VERSION ""

NS_ :

BS_:

BU_: DEBUG BMS DCM FSM PDM DIM INVL INVR

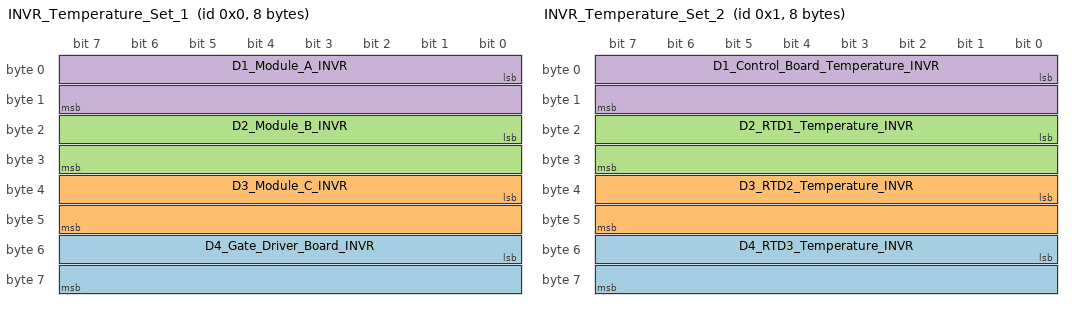
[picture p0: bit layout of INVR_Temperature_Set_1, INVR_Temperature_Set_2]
BO_ 0 INVR_Temperature_Set_1: 8 INVR
SG_ D4_Gate_Driver_Board_INVR : 48|16@1- (0.1,0) [-3276.8|3276.7] "degC" DEBUG
SG_ D3_Module_C_INVR : 32|16@1- (0.1,0) [-3276.8|3276.7] "degC" DEBUG
SG_ D2_Module_B_INVR : 16|16@1- (0.1,0) [-3276.8|3276.7] "degC" DEBUG
SG_ D1_Module_A_INVR : 0|16@1- (0.1,0) [-3276.8|3276.7] "degC" DEBUG

BO_ 1 INVR_Temperature_Set_2: 8 INVR
SG_ D4_RTD3_Temperature_INVR : 48|16@1- (0.1,0) [-3276.8|3276.7] "degC" DEBUG
SG_ D3_RTD2_Temperature_INVR : 32|16@1- (0.1,0) [-3276.8|3276.7] "degC" DEBUG
SG_ D2_RTD1_Temperature_INVR : 16|16@1- (0.1,0) [-3276.8|3276.7] "degC" DEBUG
SG_ D1_Control_Board_Temperature_INVR : 0|16@1- (0.1,0) [-3276.8|3276.7] "degC" DEBUG

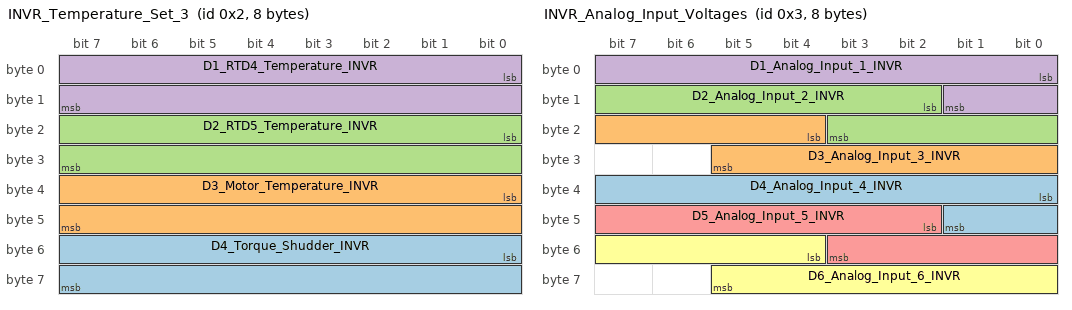
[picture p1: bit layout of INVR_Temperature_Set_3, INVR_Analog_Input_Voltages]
BO_ 2 INVR_Temperature_Set_3: 8 INVR
SG_ D4_Torque_Shudder_INVR : 48|16@1- (0.1,0) [-3276.8|3276.7] "Nm" DEBUG
SG_ D3_Motor_Temperature_INVR : 32|16@1- (0.1,0) [-3276.8|3276.7] "degC" DEBUG
SG_ D2_RTD5_Temperature_INVR : 16|16@1- (0.1,0) [-3276.8|3276.7] "degC" DEBUG
SG_ D1_RTD4_Temperature_INVR : 0|16@1- (0.1,0) [-3276.8|3276.7] "degC" DEBUG

BO_ 3 INVR_Analog_Input_Voltages: 8 INVR
SG_ D4_Analog_Input_4_INVR : 32|10@1+ (0.01,0) [0|10.23] "V" DEBUG
SG_ D3_Analog_Input_3_INVR : 20|10@1+ (0.01,0) [0|10.23] "V" DEBUG
SG_ D2_Analog_Input_2_INVR : 10|10@1+ (0.01,0) [0|10.23] "V" DEBUG
SG_ D1_Analog_Input_1_INVR : 0|10@1+ (0.01,0) [0|10.23] "V" DEBUG
SG_ D5_Analog_Input_5_INVR : 42|10@1+ (0.01,0) [0|10.23] "V" DEBUG
SG_ D6_Analog_Input_6_INVR : 52|10@1+ (0.01,0) [0|10.23] "V" DEBUG

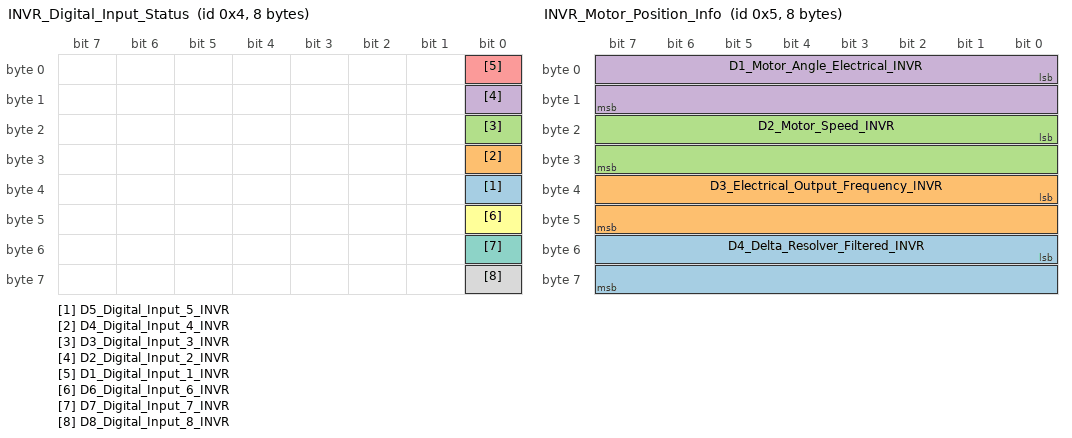
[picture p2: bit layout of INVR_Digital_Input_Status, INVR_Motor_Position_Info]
BO_ 4 INVR_Digital_Input_Status: 8 INVR
SG_ D5_Digital_Input_5_INVR : 32|1@1+ (1,0) [0|1] "boolean" DEBUG
SG_ D4_Digital_Input_4_INVR : 24|1@1+ (1,0) [0|1] "boolean" DEBUG
SG_ D3_Digital_Input_3_INVR : 16|1@1+ (1,0) [0|1] "boolean" DEBUG
SG_ D2_Digital_Input_2_INVR : 8|1@1+ (1,0) [0|1] "boolean" DEBUG
SG_ D1_Digital_Input_1_INVR : 0|1@1+ (1,0) [0|1] "boolean" DEBUG
SG_ D6_Digital_Input_6_INVR : 40|1@1+ (1,0) [0|1] "boolean" DEBUG
SG_ D7_Digital_Input_7_INVR : 48|1@1+ (1,0) [0|1] "boolean" DEBUG
SG_ D8_Digital_Input_8_INVR : 56|1@1+ (1,0) [0|1] "boolean" DEBUG

BO_ 5 INVR_Motor_Position_Info: 8 INVR
SG_ D4_Delta_Resolver_Filtered_INVR : 48|16@1- (0.1,0) [-3276.8|3276.7] "deg" DEBUG
SG_ D3_Electrical_Output_Frequency_INVR : 32|16@1- (0.1,0) [-3276.8|3276.7] "hz" DEBUG
SG_ D2_Motor_Speed_INVR : 16|16@1- (1,0) [-32768|32767] "rpm" DEBUG
SG_ D1_Motor_Angle_Electrical_INVR : 0|16@1+ (0.1,0) [0|6553.5] "deg" DEBUG

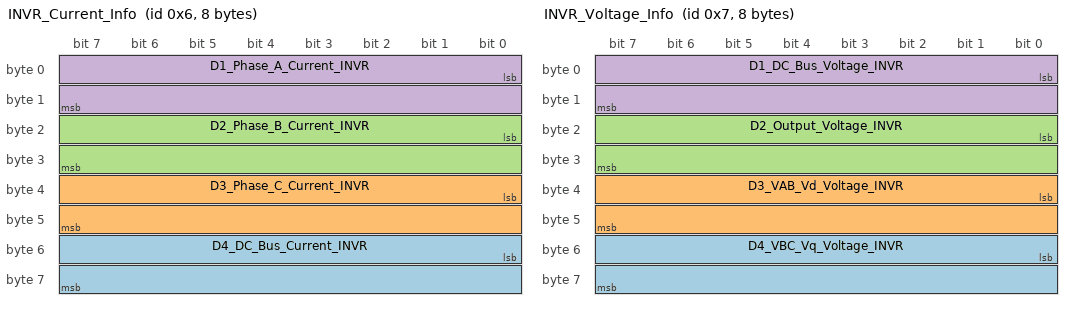
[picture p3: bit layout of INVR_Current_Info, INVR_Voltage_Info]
BO_ 6 INVR_Current_Info: 8 INVR
SG_ D4_DC_Bus_Current_INVR : 48|16@1- (0.1,0) [-3276.8|3276.7] "A" DEBUG
SG_ D3_Phase_C_Current_INVR : 32|16@1- (0.1,0) [-3276.8|3276.7] "A" DEBUG
SG_ D2_Phase_B_Current_INVR : 16|16@1- (0.1,0) [-3276.8|3276.7] "A" DEBUG
SG_ D1_Phase_A_Current_INVR : 0|16@1- (0.1,0) [-3276.8|3276.7] "A" DEBUG

BO_ 7 INVR_Voltage_Info: 8 INVR
SG_ D4_VBC_Vq_Voltage_INVR : 48|16@1- (0.1,0) [-3276.8|3276.7] "V" DEBUG
SG_ D3_VAB_Vd_Voltage_INVR : 32|16@1- (0.1,0) [-3276.8|3276.7] "V" DEBUG
SG_ D2_Output_Voltage_INVR : 16|16@1- (0.1,0) [-3276.8|3276.7] "V" DEBUG
SG_ D1_DC_Bus_Voltage_INVR : 0|16@1- (0.1,0) [-3276.8|3276.7] "V" DEBUG

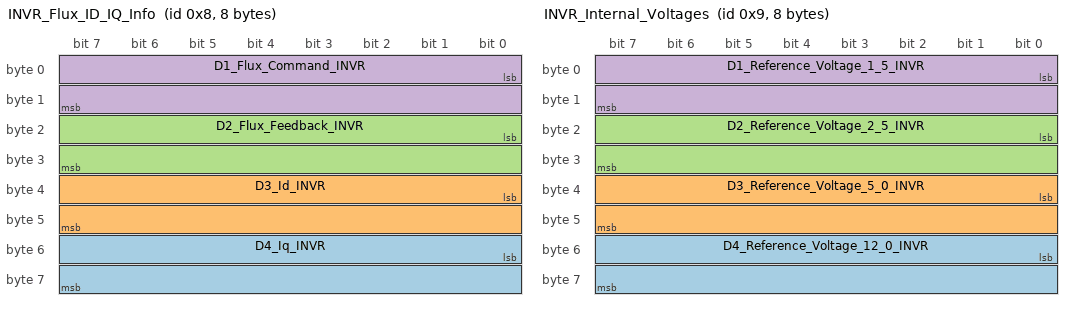
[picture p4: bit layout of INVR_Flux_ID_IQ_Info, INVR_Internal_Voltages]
BO_ 8 INVR_Flux_ID_IQ_Info: 8 INVR
SG_ D4_Iq_INVR : 48|16@1- (0.1,0) [-3276.8|3276.7] "A" DEBUG
SG_ D3_Id_INVR : 32|16@1- (0.1,0) [-3276.8|3276.7] "A" DEBUG
SG_ D2_Flux_Feedback_INVR : 16|16@1- (0.001,0) [-32.768|32.767] "Wb" DEBUG
SG_ D1_Flux_Command_INVR : 0|16@1- (0.001,0) [-32.768|32.767] "Wb" DEBUG

BO_ 9 INVR_Internal_Voltages: 8 INVR
SG_ D4_Reference_Voltage_12_0_INVR : 48|16@1- (0.01,0) [-327.68|327.67] "V" DEBUG
SG_ D3_Reference_Voltage_5_0_INVR : 32|16@1- (0.01,0) [-327.68|327.67] "V" DEBUG
SG_ D2_Reference_Voltage_2_5_INVR : 16|16@1- (0.01,0) [-327.68|327.67] "V" DEBUG
SG_ D1_Reference_Voltage_1_5_INVR : 0|16@1- (0.01,0) [-327.68|327.67] "V" DEBUG

BO_ 10 INVR_Internal_States: 8 INVR
SG_ D7_Direction_Command_INVR : 56|1@1+ (1,0) [0|1] "" DEBUG
SG_ D6_Inverter_Enable_State_INVR : 48|1@1+ (1,0) [0|1] "" DEBUG
SG_ D3_Relay_3_Status_INVR : 26|1@1+ (1,0) [0|1] "" DEBUG
SG_ D3_Relay_4_Status_INVR : 27|1@1+ (1,0) [0|1] "" DEBUG
SG_ D3_Relay_2_Status_INVR : 25|1@1+ (1,0) [0|1] "" DEBUG
SG_ D4_Inverter_Run_Mode_INVR : 32|1@1+ (1,0) [0|1] "" DEBUG
SG_ D5_Inverter_Command_Mode_INVR : 40|1@1+ (1,0) [0|1] "" DEBUG
SG_ D3_Relay_1_Status_INVR : 24|1@1+ (1,0) [0|1] "" DEBUG
SG_ D2_Inverter_State_INVR : 16|8@1+ (1,0) [0|255] "" DEBUG
SG_ D1_VSM_State_INVR : 0|8@1+ (1,0) [0|15] "" DCM
SG_ D6_Inverter_Enable_Lockout_INVR : 55|1@1+ (1,0) [0|1] "" DEBUG
SG_ D4_Inverter_Discharge_State_INVR : 37|3@1+ (1,0) [0|7] "" DEBUG
SG_ D3_Relay_5_Status_INVR : 28|1@1+ (1,0) [0|1] "" DEBUG
SG_ D3_Relay_6_Status_INVR : 29|1@1+ (1,0) [0|1] "" DEBUG
SG_ D7_BMS_Active_INVR : 57|1@1+ (1,0) [0|1] "" DEBUG
SG_ D7_BMS_Torque_Limiting_INVR : 58|1@1+ (1,0) [0|1] "" DEBUG
SG_ D7_Max_Speed_Limiting_INVR : 59|1@1+ (1,0) [0|1] "" DEBUG
SG_ D7_Low_Speed_Limiting_INVR : 61|1@1+ (1,0) [0|1] "" DEBUG
SG_ D5_Rolling_Counter_INVR : 44|4@1+ (1,0) [0|15] "" DEBUG
SG_ D1_PWM_Frequency_INVR : 8|8@1+ (1,0) [0|255] "kHz" DEBUG
SG_ D6_Start_Mode_Active_INVR : 54|1@1+ (1,0) [0|1] "" DEBUG

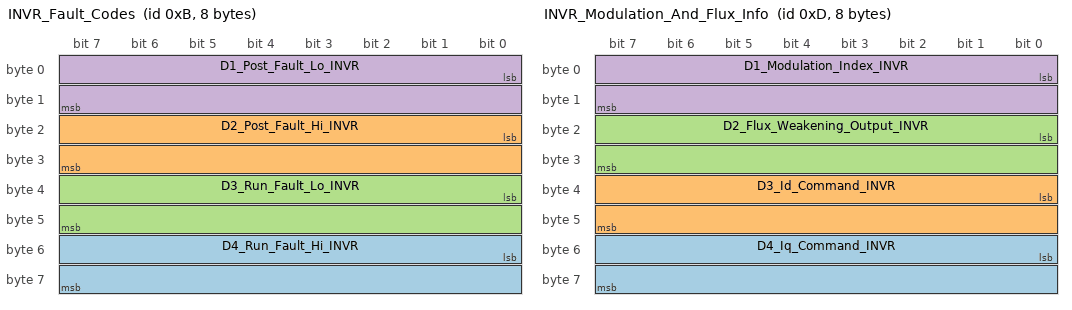
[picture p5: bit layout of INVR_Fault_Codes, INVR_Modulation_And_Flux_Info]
BO_ 11 INVR_Fault_Codes: 8 INVR
SG_ D4_Run_Fault_Hi_INVR : 48|16@1+ (1,0) [0|65535] "" DEBUG
SG_ D2_Post_Fault_Hi_INVR : 16|16@1+ (1,0) [0|65535] "" DEBUG
SG_ D3_Run_Fault_Lo_INVR : 32|16@1+ (1,0) [0|65535] "" DEBUG
SG_ D1_Post_Fault_Lo_INVR : 0|16@1+ (1,0) [0|65535] "" DEBUG

BO_ 12 INVR_Torque_And_Timer_Info: 8 INVR
SG_ D3_Power_On_Timer_INVR : 32|32@1+ (0.003,0) [0|12884800] "Sec" DEBUG
SG_ D2_Torque_Feedback_INVR : 16|16@1- (0.1,0) [-3276.8|3276.7] "Nm" DEBUG
SG_ D1_Commanded_Torque_INVR : 0|16@1- (0.1,0) [-3276.8|3276.7] "Nm" DEBUG

BO_ 13 INVR_Modulation_And_Flux_Info: 8 INVR
SG_ D4_Iq_Command_INVR : 48|16@1- (0.1,0) [-3276.8|3276.7] "A" DEBUG
SG_ D3_Id_Command_INVR : 32|16@1- (0.1,0) [-3276.8|3276.7] "A" DEBUG
SG_ D2_Flux_Weakening_Output_INVR : 16|16@1- (0.1,0) [-3276.8|3276.7] "A" DEBUG
SG_ D1_Modulation_Index_INVR : 0|16@1- (0.0001,0) [-3.2768|3.2767] "" DEBUG

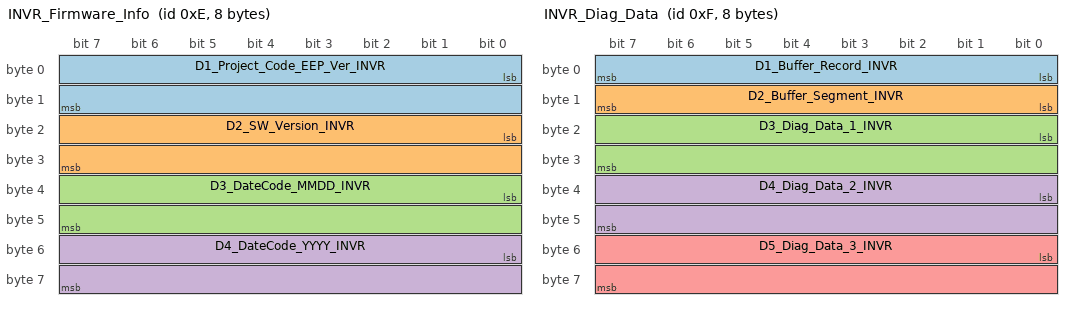
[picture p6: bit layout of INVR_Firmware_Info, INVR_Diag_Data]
BO_ 14 INVR_Firmware_Info: 8 INVR
SG_ D1_Project_Code_EEP_Ver_INVR : 0|16@1+ (1,0) [0|65535] "" DEBUG
SG_ D2_SW_Version_INVR : 16|16@1+ (1,0) [0|65535] "" DEBUG
SG_ D3_DateCode_MMDD_INVR : 32|16@1+ (1,0) [0|65535] "" DEBUG
SG_ D4_DateCode_YYYY_INVR : 48|16@1+ (1,0) [0|65535] "" DEBUG

BO_ 15 INVR_Diag_Data : 8 INVR
SG_ D1_Buffer_Record_INVR : 0|8@1+ (1,0) [0|255] "" DEBUG
SG_ D2_Buffer_Segment_INVR : 8|8@1+ (1,0) [0|5] "" DEBUG
SG_ D3_Diag_Data_1_INVR : 16|16@1- (1,0) [-32768|32767] "" DEBUG
SG_ D4_Diag_Data_2_INVR : 32|16@1- (1,0) [-32768|32767] "" DEBUG
SG_ D5_Diag_Data_3_INVR : 48|16@1- (1,0) [-32768|32767] "" DEBUG

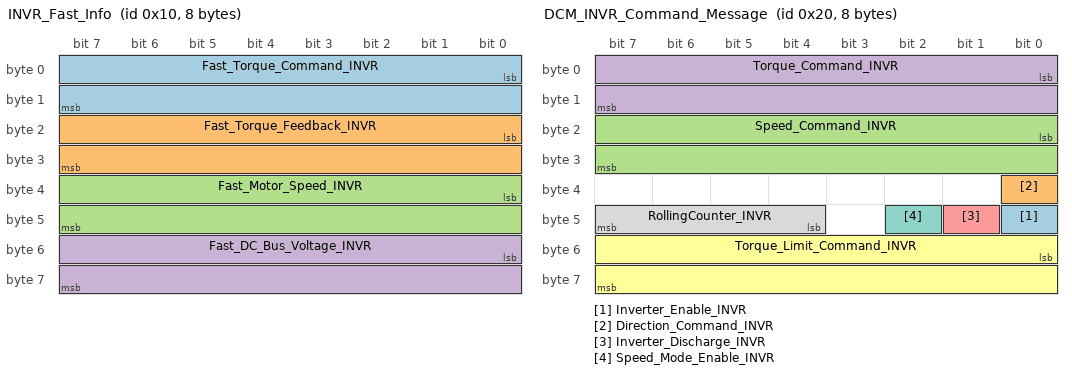
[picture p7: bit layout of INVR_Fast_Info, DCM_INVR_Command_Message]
BO_ 16 INVR_Fast_Info: 8 INVR
SG_ Fast_Torque_Command_INVR : 0|16@1- (0.1,0) [-3276.8|3276.7] "Nm" DEBUG
SG_ Fast_Torque_Feedback_INVR : 16|16@1- (0.1,0) [-3276.8|3276.7] "Nm" DEBUG
SG_ Fast_Motor_Speed_INVR : 32|16@1- (1,0) [-32768|32767] "rpm" DEBUG
SG_ Fast_DC_Bus_Voltage_INVR : 48|16@1- (0.1,0) [-3276.8|3276.7] "V" DEBUG

BO_ 32 DCM_INVR_Command_Message: 8 DCM
SG_ Inverter_Enable_INVR : 40|1@1+ (1,0) [0|1] "Bit" INVR
SG_ Direction_Command_INVR : 32|1@1+ (1,0) [0|1] "Bit" INVR
SG_ Speed_Command_INVR : 16|16@1- (1,0) [-32768|32767] "rpm" INVR
SG_ Torque_Command_INVR : 0|16@1- (0.1,0) [-3276.8|3276.7] "Nm" INVR
SG_ Inverter_Discharge_INVR : 41|1@1+ (1,0) [0|1] "Bit" INVR
SG_ Torque_Limit_Command_INVR : 48|16@1- (0.1,0) [-3276.8|3276.7] "Nm" INVR
SG_ Speed_Mode_Enable_INVR : 42|1@1+ (1,0) [0|1] "Bit" INVR
SG_ RollingCounter_INVR : 44|4@1+ (1,0) [0|15] "Bits" INVR

BO_ 33 DEBUG_INVR_Read_Write_Param_Command: 8 DEBUG
SG_ D3_Data_Command : 32|16@1- (1,0) [-32768|32767] "" INVR
SG_ D2_Read_Write_Command : 16|1@1+ (1,0) [0|1] "" INVR
SG_ D1_Parameter_Address_Command : 0|16@1+ (1,0) [0|65535] "" INVR

BO_ 34 INVR_DEBUG_Read_Write_Param_Response: 8 INVR
SG_ D2_Write_Success : 16|1@1+ (1,0) [0|1] "" DEBUG
SG_ D3_Data_Response : 32|16@1- (1,0) [-32768|32767] "" DEBUG
SG_ D1_Parameter_Address_Response : 0|16@1+ (1,0) [0|65535] "" DEBUG

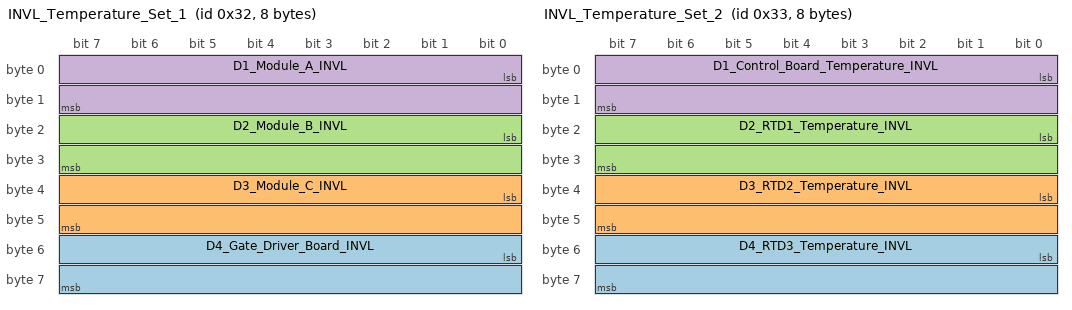
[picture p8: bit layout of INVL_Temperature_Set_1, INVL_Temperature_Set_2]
BO_ 50 INVL_Temperature_Set_1: 8 INVL
SG_ D4_Gate_Driver_Board_INVL : 48|16@1- (0.1,0) [-3276.8|3276.7] "degC" DEBUG
SG_ D3_Module_C_INVL : 32|16@1- (0.1,0) [-3276.8|3276.7] "degC" DEBUG
SG_ D2_Module_B_INVL : 16|16@1- (0.1,0) [-3276.8|3276.7] "degC" DEBUG
SG_ D1_Module_A_INVL : 0|16@1- (0.1,0) [-3276.8|3276.7] "degC" DEBUG

BO_ 51 INVL_Temperature_Set_2: 8 INVL
SG_ D4_RTD3_Temperature_INVL : 48|16@1- (0.1,0) [-3276.8|3276.7] "degC" DEBUG
SG_ D3_RTD2_Temperature_INVL : 32|16@1- (0.1,0) [-3276.8|3276.7] "degC" DEBUG
SG_ D2_RTD1_Temperature_INVL : 16|16@1- (0.1,0) [-3276.8|3276.7] "degC" DEBUG
SG_ D1_Control_Board_Temperature_INVL : 0|16@1- (0.1,0) [-3276.8|3276.7] "degC" DEBUG

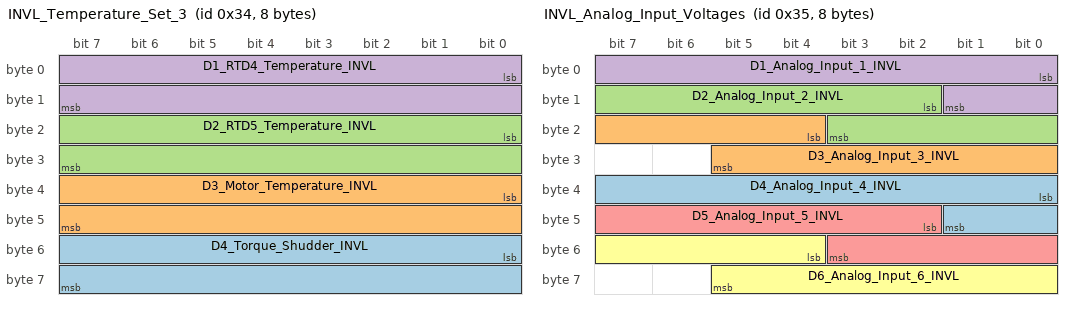
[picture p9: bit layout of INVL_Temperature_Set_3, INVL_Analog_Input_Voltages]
BO_ 52 INVL_Temperature_Set_3: 8 INVL
SG_ D4_Torque_Shudder_INVL : 48|16@1- (0.1,0) [-3276.8|3276.7] "Nm" DEBUG
SG_ D3_Motor_Temperature_INVL : 32|16@1- (0.1,0) [-3276.8|3276.7] "degC" DEBUG
SG_ D2_RTD5_Temperature_INVL : 16|16@1- (0.1,0) [-3276.8|3276.7] "degC" DEBUG
SG_ D1_RTD4_Temperature_INVL : 0|16@1- (0.1,0) [-3276.8|3276.7] "degC" DEBUG

BO_ 53 INVL_Analog_Input_Voltages: 8 INVL
SG_ D4_Analog_Input_4_INVL : 32|10@1+ (0.01,0) [0|10.23] "V" DEBUG
SG_ D3_Analog_Input_3_INVL : 20|10@1+ (0.01,0) [0|10.23] "V" DEBUG
SG_ D2_Analog_Input_2_INVL : 10|10@1+ (0.01,0) [0|10.23] "V" DEBUG
SG_ D1_Analog_Input_1_INVL : 0|10@1+ (0.01,0) [0|10.23] "V" DEBUG
SG_ D5_Analog_Input_5_INVL : 42|10@1+ (0.01,0) [0|10.23] "V" DEBUG
SG_ D6_Analog_Input_6_INVL : 52|10@1+ (0.01,0) [0|10.23] "V" DEBUG

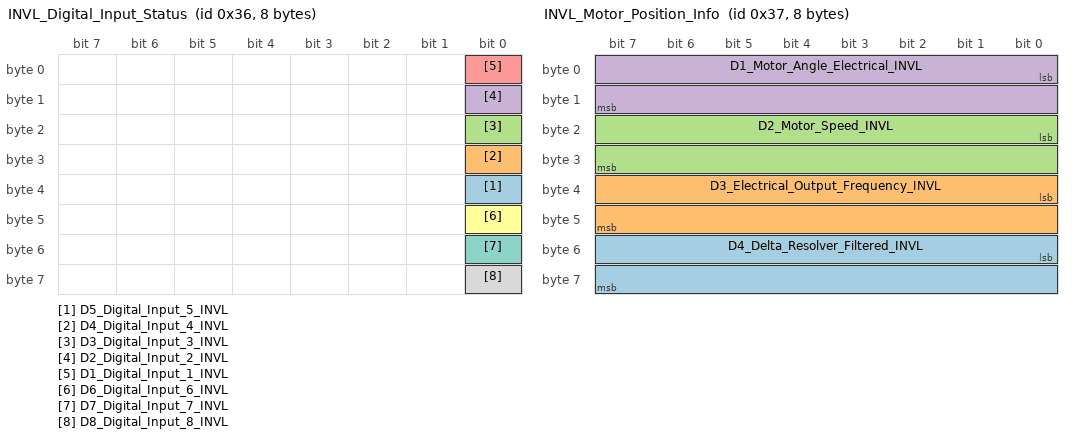
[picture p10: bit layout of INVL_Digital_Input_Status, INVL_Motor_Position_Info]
BO_ 54 INVL_Digital_Input_Status: 8 INVL
SG_ D5_Digital_Input_5_INVL : 32|1@1+ (1,0) [0|1] "boolean" DEBUG
SG_ D4_Digital_Input_4_INVL : 24|1@1+ (1,0) [0|1] "boolean" DEBUG
SG_ D3_Digital_Input_3_INVL : 16|1@1+ (1,0) [0|1] "boolean" DEBUG
SG_ D2_Digital_Input_2_INVL : 8|1@1+ (1,0) [0|1] "boolean" DEBUG
SG_ D1_Digital_Input_1_INVL : 0|1@1+ (1,0) [0|1] "boolean" DEBUG
SG_ D6_Digital_Input_6_INVL : 40|1@1+ (1,0) [0|1] "boolean" DEBUG
SG_ D7_Digital_Input_7_INVL : 48|1@1+ (1,0) [0|1] "boolean" DEBUG
SG_ D8_Digital_Input_8_INVL : 56|1@1+ (1,0) [0|1] "boolean" DEBUG

BO_ 55 INVL_Motor_Position_Info: 8 INVL
SG_ D4_Delta_Resolver_Filtered_INVL : 48|16@1- (0.1,0) [-3276.8|3276.7] "deg" DEBUG
SG_ D3_Electrical_Output_Frequency_INVL : 32|16@1- (0.1,0) [-3276.8|3276.7] "hz" DEBUG
SG_ D2_Motor_Speed_INVL : 16|16@1- (1,0) [-32768|32767] "rpm" DEBUG
SG_ D1_Motor_Angle_Electrical_INVL : 0|16@1+ (0.1,0) [0|6553.5] "deg" DEBUG

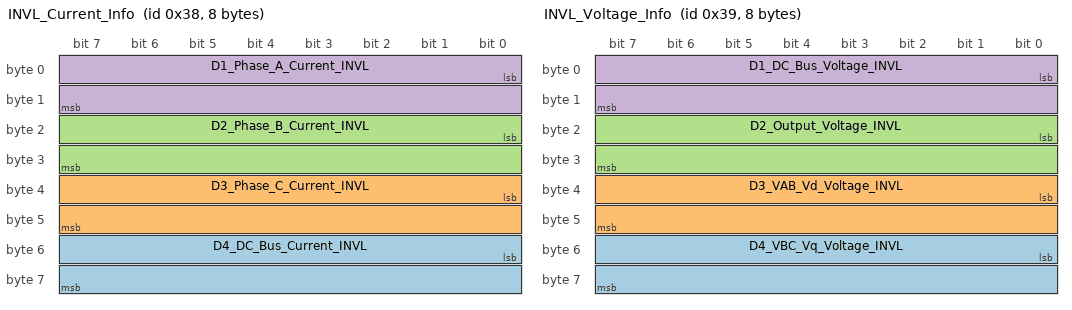
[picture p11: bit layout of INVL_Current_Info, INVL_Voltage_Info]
BO_ 56 INVL_Current_Info: 8 INVL
SG_ D4_DC_Bus_Current_INVL : 48|16@1- (0.1,0) [-3276.8|3276.7] "A" DEBUG
SG_ D3_Phase_C_Current_INVL : 32|16@1- (0.1,0) [-3276.8|3276.7] "A" DEBUG
SG_ D2_Phase_B_Current_INVL : 16|16@1- (0.1,0) [-3276.8|3276.7] "A" DEBUG
SG_ D1_Phase_A_Current_INVL : 0|16@1- (0.1,0) [-3276.8|3276.7] "A" DEBUG

BO_ 57 INVL_Voltage_Info: 8 INVL
SG_ D4_VBC_Vq_Voltage_INVL : 48|16@1- (0.1,0) [-3276.8|3276.7] "V" DEBUG
SG_ D3_VAB_Vd_Voltage_INVL : 32|16@1- (0.1,0) [-3276.8|3276.7] "V" DEBUG
SG_ D2_Output_Voltage_INVL : 16|16@1- (0.1,0) [-3276.8|3276.7] "V" DEBUG
SG_ D1_DC_Bus_Voltage_INVL : 0|16@1- (0.1,0) [-3276.8|3276.7] "V" DEBUG

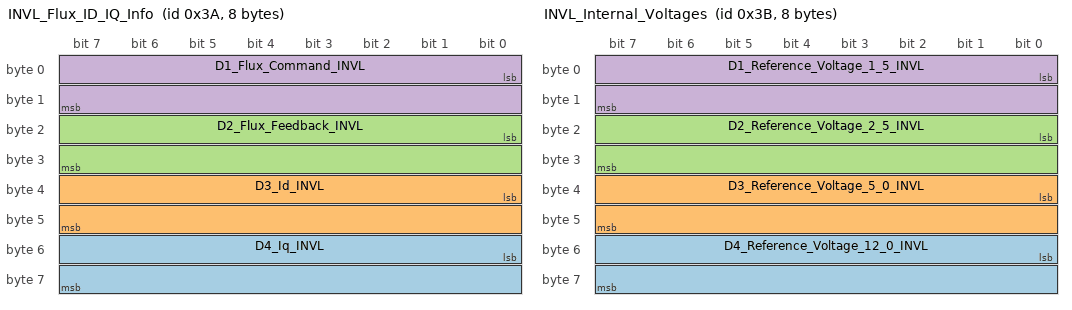
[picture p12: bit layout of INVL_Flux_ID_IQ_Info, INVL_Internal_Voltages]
BO_ 58 INVL_Flux_ID_IQ_Info: 8 INVL
SG_ D4_Iq_INVL : 48|16@1- (0.1,0) [-3276.8|3276.7] "A" DEBUG
SG_ D3_Id_INVL : 32|16@1- (0.1,0) [-3276.8|3276.7] "A" DEBUG
SG_ D2_Flux_Feedback_INVL : 16|16@1- (0.001,0) [-32.768|32.767] "Wb" DEBUG
SG_ D1_Flux_Command_INVL : 0|16@1- (0.001,0) [-32.768|32.767] "Wb" DEBUG

BO_ 59 INVL_Internal_Voltages: 8 INVL
SG_ D4_Reference_Voltage_12_0_INVL : 48|16@1- (0.01,0) [-327.68|327.67] "V" DEBUG
SG_ D3_Reference_Voltage_5_0_INVL : 32|16@1- (0.01,0) [-327.68|327.67] "V" DEBUG
SG_ D2_Reference_Voltage_2_5_INVL : 16|16@1- (0.01,0) [-327.68|327.67] "V" DEBUG
SG_ D1_Reference_Voltage_1_5_INVL : 0|16@1- (0.01,0) [-327.68|327.67] "V" DEBUG

BO_ 60 INVL_Internal_States: 8 INVL
SG_ D7_Direction_Command_INVL : 56|1@1+ (1,0) [0|1] "" DEBUG
SG_ D6_Inverter_Enable_State_INVL : 48|1@1+ (1,0) [0|1] "" DEBUG
SG_ D3_Relay_3_Status_INVL : 26|1@1+ (1,0) [0|1] ""  DEBUG
SG_ D3_Relay_4_Status_INVL : 27|1@1+ (1,0) [0|1] ""  DEBUG
SG_ D3_Relay_2_Status_INVL : 25|1@1+ (1,0) [0|1] ""  DEBUG
SG_ D4_Inverter_Run_Mode_INVL : 32|1@1+ (1,0) [0|1] "" DEBUG
SG_ D5_Inverter_Command_Mode_INVL : 40|1@1+ (1,0) [0|1] "" DEBUG
SG_ D3_Relay_1_Status_INVL : 24|1@1+ (1,0) [0|1] "" DEBUG
SG_ D2_Inverter_State_INVL : 16|8@1+ (1,0) [0|255] "" DEBUG
SG_ D1_VSM_State_INVL : 0|8@1+ (1,0) [0|15] "" DCM
SG_ D6_Inverter_Enable_Lockout_INVL : 55|1@1+ (1,0) [0|1] "" DEBUG
SG_ D4_Inverter_Discharge_State_INVL : 37|3@1+ (1,0) [0|7] "" DEBUG
SG_ D3_Relay_5_Status_INVL : 28|1@1+ (1,0) [0|1] "" DEBUG
SG_ D3_Relay_6_Status_INVL : 29|1@1+ (1,0) [0|1] "" DEBUG
SG_ D7_BMS_Active_INVL : 57|1@1+ (1,0) [0|1] "" DEBUG
SG_ D7_BMS_Torque_Limiting_INVL : 58|1@1+ (1,0) [0|1] "" DEBUG
SG_ D7_Max_Speed_Limiting_INVL : 59|1@1+ (1,0) [0|1] "" DEBUG
SG_ D7_Low_Speed_Limiting_INVL : 61|1@1+ (1,0) [0|1] "" DEBUG
SG_ D5_Rolling_Counter_INVL : 44|4@1+ (1,0) [0|15] "" DEBUG
SG_ D1_PWM_Frequency_INVL : 8|8@1+ (1,0) [0|255] "kHz" DEBUG
SG_ D6_Start_Mode_Active_INVL : 54|1@1+ (1,0) [0|1] "" DEBUG

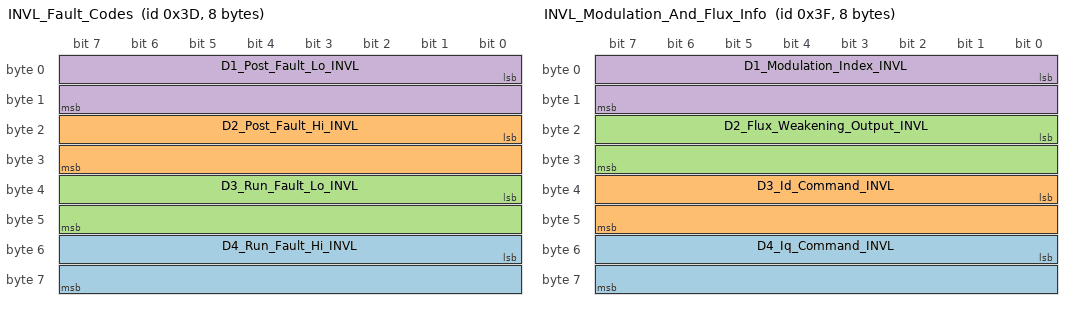
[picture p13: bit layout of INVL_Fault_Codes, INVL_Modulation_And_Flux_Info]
BO_ 61 INVL_Fault_Codes: 8 INVL
SG_ D4_Run_Fault_Hi_INVL : 48|16@1+ (1,0) [0|65535] "" DEBUG
SG_ D2_Post_Fault_Hi_INVL : 16|16@1+ (1,0) [0|65535] "" DEBUG
SG_ D3_Run_Fault_Lo_INVL : 32|16@1+ (1,0) [0|65535] "" DEBUG
SG_ D1_Post_Fault_Lo_INVL : 0|16@1+ (1,0) [0|65535] "" DEBUG

BO_ 62 INVL_Torque_And_Timer_Info: 8 INVL
SG_ D3_Power_On_Timer_INVL : 32|32@1+ (0.003,0) [0|12884800] "Sec" DEBUG
SG_ D2_Torque_Feedback_INVL : 16|16@1- (0.1,0) [-3276.8|3276.7] "Nm" DEBUG
SG_ D1_Commanded_Torque_INVL : 0|16@1- (0.1,0) [-3276.8|3276.7] "Nm" DEBUG

BO_ 63 INVL_Modulation_And_Flux_Info: 8 INVL
SG_ D4_Iq_Command_INVL : 48|16@1- (0.1,0) [-3276.8|3276.7] "A" DEBUG
SG_ D3_Id_Command_INVL : 32|16@1- (0.1,0) [-3276.8|3276.7] "A" DEBUG
SG_ D2_Flux_Weakening_Output_INVL : 16|16@1- (0.1,0) [-3276.8|3276.7] "A" DEBUG
SG_ D1_Modulation_Index_INVL : 0|16@1- (0.0001,0) [-3.2768|3.2767] "" DEBUG

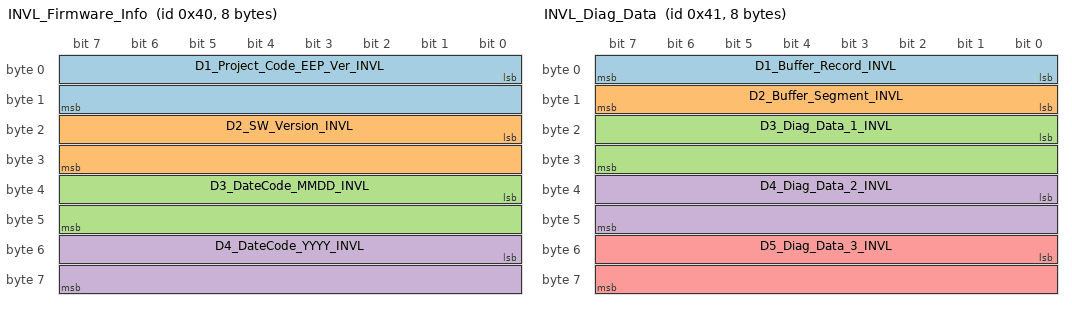
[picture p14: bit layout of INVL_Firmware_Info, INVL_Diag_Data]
BO_ 64 INVL_Firmware_Info: 8 INVL
SG_ D1_Project_Code_EEP_Ver_INVL : 0|16@1+ (1,0) [0|65535] "" DEBUG
SG_ D2_SW_Version_INVL : 16|16@1+ (1,0) [0|65535] "" DEBUG
SG_ D3_DateCode_MMDD_INVL : 32|16@1+ (1,0) [0|65535] "" DEBUG
SG_ D4_DateCode_YYYY_INVL : 48|16@1+ (1,0) [0|65535] "" DEBUG

BO_ 65 INVL_Diag_Data: 8 INVL
SG_ D1_Buffer_Record_INVL : 0|8@1+ (1,0) [0|255] "" DEBUG
SG_ D2_Buffer_Segment_INVL : 8|8@1+ (1,0) [0|5] "" DEBUG
SG_ D3_Diag_Data_1_INVL : 16|16@1- (1,0) [-32768|32767] "" DEBUG
SG_ D4_Diag_Data_2_INVL : 32|16@1- (1,0) [-32768|32767] "" DEBUG
SG_ D5_Diag_Data_3_INVL : 48|16@1- (1,0) [-32768|32767] "" DEBUG

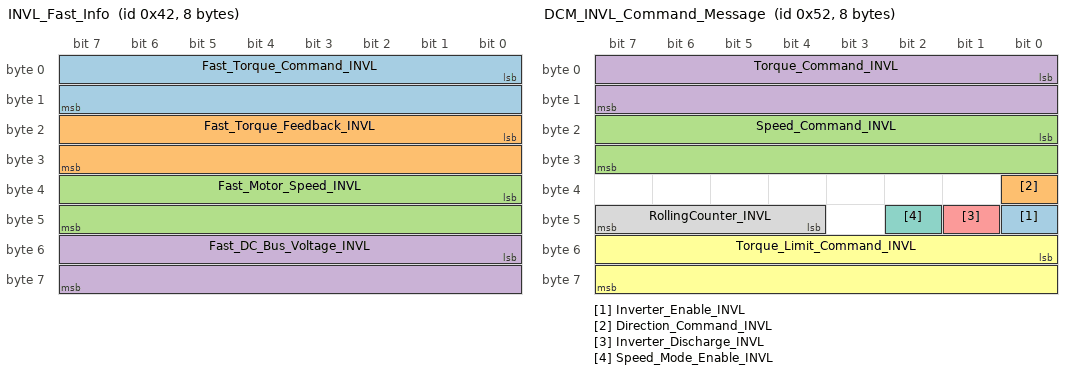
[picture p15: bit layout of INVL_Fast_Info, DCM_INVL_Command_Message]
BO_ 66 INVL_Fast_Info: 8 INVL
SG_ Fast_Torque_Command_INVL : 0|16@1- (0.1,0) [-3276.8|3276.7] "Nm" DEBUG
SG_ Fast_Torque_Feedback_INVL : 16|16@1- (0.1,0) [-3276.8|3276.7] "Nm" DEBUG
SG_ Fast_Motor_Speed_INVL : 32|16@1- (1,0) [-32768|32767] "rpm" DEBUG
SG_ Fast_DC_Bus_Voltage_INVL : 48|16@1- (0.1,0) [-3276.8|3276.7] "V" DEBUG

BO_ 82 DCM_INVL_Command_Message: 8 DCM
SG_ Inverter_Enable_INVL : 40|1@1+ (1,0) [0|1] "Bit" INVL
SG_ Direction_Command_INVL : 32|1@1+ (1,0) [0|1] "Bit" INVL
SG_ Speed_Command_INVL : 16|16@1- (1,0) [-32768|32767] "rpm" INVL
SG_ Torque_Command_INVL : 0|16@1- (0.1,0) [-3276.8|3276.7] "Nm" INVL
SG_ Inverter_Discharge_INVL : 41|1@1+ (1,0) [0|1] "Bit" INVL
SG_ Torque_Limit_Command_INVL : 48|16@1- (0.1,0) [-3276.8|3276.7] "Nm" INVL
SG_ Speed_Mode_Enable_INVL : 42|1@1+ (1,0) [0|1] "Bit" INVL
SG_ RollingCounter_INVL : 44|4@1+ (1,0) [0|15] "Bits" INVL

BO_ 83 DEBUG_INVL_Read_Write_Param_Command: 8 DEBUG
SG_ D3_Data_Command : 32|16@1- (1,0) [-32768|32767] "" INVL
SG_ D2_Read_Write_Command : 16|1@1+ (1,0) [0|1] "" INVL
SG_ D1_Parameter_Address_Command : 0|16@1+ (1,0) [0|65535] "" INVL

BO_ 84 INVL_DEBUG_Read_Write_Param_Response: 8 INVL
SG_ D2_Write_Success : 16|1@1+ (1,0) [0|1] "" DEBUG
SG_ D3_Data_Response : 32|16@1- (1,0) [-32768|32767] "" DEBUG
SG_ D1_Parameter_Address_Response : 0|16@1+ (1,0) [0|65535] "" DEBUG

BO_ 100 BMS_HEARTBEAT: 1 BMS
SG_ DUMMY_VARIABLE : 0|1@1+ (1,0) [0|1] "" FSM,DCM,PDM,DIM

BO_ 101 BMS_CAN_FIFO_OVERFLOW: 8 BMS
SG_ tx_overflow_count : 0|32@1+ (1,0) [0|4294967295] "" DEBUG
SG_ rx_overflow_count : 32|32@1+ (1,0) [0|4294967295] "" DEBUG

BO_ 102 BMS_STARTUP: 0 BMS

BO_ 103 BMS_WATCHDOG_TIMEOUT : 8 BMS
SG_ TASK_NAME : 0|64@1+ (1,0) [0|0] "" DEBUG

BO_ 104 BMS_NON_CRITICAL_ERRORS: 8 BMS
SG_ STACK_WATERMARK_ABOVE_THRESHOLD_TASK1HZ : 0|1@1+ (1,0) [0|1] "" DEBUG
SG_ STACK_WATERMARK_ABOVE_THRESHOLD_TASK1KHZ : 1|1@1+ (1,0) [0|1] "" DEBUG
SG_ STACK_WATERMARK_ABOVE_THRESHOLD_TASKCANRX : 2|1@1+ (1,0) [0|1] "" DEBUG
SG_ STACK_WATERMARK_ABOVE_THRESHOLD_TASKCANTX : 3|1@1+ (1,0) [0|1] "" DEBUG
SG_ WATCHDOG_TIMEOUT : 4|1@1+ (1,0) [0|1] "" DEBUG
SG_ SEGMENT_0_VOLTAGE_OUT_OF_RANGE : 6|2@1+ (1,0) [0|2] "" DEBUG
SG_ SEGMENT_1_VOLTAGE_OUT_OF_RANGE : 8|2@1+ (1,0) [0|2] "" DEBUG
SG_ SEGMENT_2_VOLTAGE_OUT_OF_RANGE : 10|2@1+ (1,0) [0|2] "" DEBUG
SG_ SEGMENT_3_VOLTAGE_OUT_OF_RANGE : 12|2@1+ (1,0) [0|2] "" DEBUG
SG_ SEGMENT_4_VOLTAGE_OUT_OF_RANGE : 14|2@1+ (1,0) [0|2] "" DEBUG
SG_ SEGMENT_5_VOLTAGE_OUT_OF_RANGE : 16|2@1+ (1,0) [0|2] "" DEBUG
SG_ PACK_VOLTAGE_OUT_OF_RANGE : 18|2@1+ (1,0) [0|2] "" DEBUG
SG_ AVERAGE_CELL_VOLTAGE_OUT_OF_RANGE : 20|2@1+ (1,0) [0|2] "" DEBUG
SG_ CELL_MONITOR_0_DIE_TEMP_OUT_OF_RANGE : 22|2@1+ (1,0) [0|2] "" DEBUG
SG_ CELL_MONITOR_1_DIE_TEMP_OUT_OF_RANGE : 24|2@1+ (1,0) [0|2] "" DEBUG
SG_ CELL_MONITOR_2_DIE_TEMP_OUT_OF_RANGE : 26|2@1+ (1,0) [0|2] "" DEBUG
SG_ CELL_MONITOR_3_DIE_TEMP_OUT_OF_RANGE : 28|2@1+ (1,0) [0|2] "" DEBUG
SG_ CELL_MONITOR_4_DIE_TEMP_OUT_OF_RANGE : 30|2@1+ (1,0) [0|2] "" DEBUG
SG_ CELL_MONITOR_5_DIE_TEMP_OUT_OF_RANGE : 32|2@1+ (1,0) [0|2] "" DEBUG
SG_ ITMP_CHARGER_HAS_OVERFLOW : 34|1@1+ (1,0) [0|1] "" DEBUG

BO_ 105 BMS_IMD: 8 BMS
SG_ Condition M : 0|3@1+ (1,0) [0|6] "" DEBUG
SG_ Seconds_Since_Power_On : 3|16@1+ (1,0) [0|255] "Seconds" DEBUG
SG_ Valid_Duty_Cycle : 19|1@1+ (1,0) [0|1] "" DEBUG
SG_ Insulation_Measurement_DCP_10Hz m1 : 20|16@1+ (1,0) [0|65535] "kOhm" DEBUG
SG_ Insulation_Measurement_DCP_20Hz m2 : 20|16@1+ (1,0) [0|65535] "kOhm" DEBUG
SG_ Speed_Start_Status_30Hz m3 : 20|16@1+ (1,0) [0|65535] "" DEBUG
SG_ OK_HS : 36|1@1+ (1,0) [0|1] "" DIM

BO_ 106 BMS_IMD_PWM_OUTPUT : 8 BMS
SG_ Duty_Cycle : 0|32@1- (1,0) [0|1E2] "%" DEBUG
SG_ Frequency : 32|32@1- (1,0) [0|1E4] "Hz" DEBUG

BO_ 107 BMS_STATE_MACHINE : 1 BMS
SG_ State : 0|8@1+ (1,0) [0|255] "" DEBUG

BO_ 108 BMS_STATE_OF_CHARGE: 4 BMS
SG_ State_Of_Charge : 0|32@1- (1,0) [0|1E2] "%" DIM

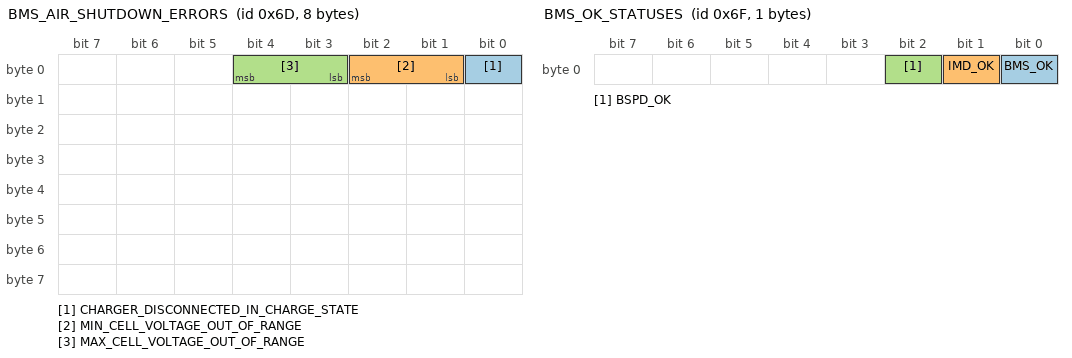
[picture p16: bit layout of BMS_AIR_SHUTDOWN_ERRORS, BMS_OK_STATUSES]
BO_ 109 BMS_AIR_SHUTDOWN_ERRORS: 8 BMS
SG_ CHARGER_DISCONNECTED_IN_CHARGE_STATE : 0|1@1+ (1,0) [0|1] "" DCM
SG_ MIN_CELL_VOLTAGE_OUT_OF_RANGE : 1|2@1+ (1,0) [0|2] "" DCM
SG_ MAX_CELL_VOLTAGE_OUT_OF_RANGE : 3|2@1+ (1,0) [0|2] "" DCM

BO_ 110 BMS_CHARGER: 1 BMS
SG_ Is_Connected : 0|1@1+ (1,0) [0|1] "" DEBUG

BO_ 111 BMS_OK_STATUSES: 1 BMS
SG_ BMS_OK : 0|1@1+ (1,0) [0|1] "" DEBUG
SG_ IMD_OK : 1|1@1+ (1,0) [0|1] "" DEBUG
SG_ BSPD_OK : 2|1@1+ (1,0) [0|1] "" DEBUG

BO_ 112 BMS_AIR_STATES: 1 BMS
SG_ AIR_POSITIVE : 0|1@1+ (1,0) [0|1] "" FSM,DCM,PDM
SG_ AIR_NEGATIVE : 1|1@1+ (1,0) [0|1] "" FSM,DCM,PDM

BO_ 113 BMS_MOTOR_SHUTDOWN_ERRORS: 8 BMS
SG_ DUMMY_MOTOR_SHUTDOWN : 0|1@1+ (1,0) [0|1] "" DCM

BO_ 114 BMS_ACCUMULATOR_MIN_AND_MAX_VOLTAGES: 8 BMS
SG_ MIN_CELL_VOLTAGE : 0|32@1+ (1,0) [3.0|4.20] "V" DEBUG
SG_ MAX_CELL_VOLTAGE : 32|32@1+ (1,0) [3.0|4.20] "V" DEBUG

BO_ 115 BMS_ACCUMULATOR_PACK: 4 BMS
SG_ PACK_VOLTAGE : 0|32@1+ (1,0) [288.0|403.2] "V" DEBUG

BO_ 116 BMS_ACCUMULATOR_AVERAGE_CELL: 4 BMS
SG_ AVERAGE_CELL_VOLTAGE : 0|32@1+ (1,0) [3.0|4.20] "V" DEBUG

BO_ 117 BMS_ACCUMULATOR_SEGMENT_0: 4 BMS
SG_ SEGMENT_0_VOLTAGE : 0|32@1+ (1,0) [48.0|67.2] "V" DEBUG

BO_ 118 BMS_ACCUMULATOR_SEGMENT_1: 4 BMS
SG_ SEGMENT_1_VOLTAGE : 0|32@1+ (1,0) [48.0|67.2] "V" DEBUG

BO_ 119 BMS_ACCUMULATOR_SEGMENT_2: 4 BMS
SG_ SEGMENT_2_VOLTAGE : 0|32@1+ (1,0) [48.0|67.2] "V" DEBUG

BO_ 120 BMS_ACCUMULATOR_SEGMENT_3: 4 BMS
SG_ SEGMENT_3_VOLTAGE : 0|32@1+ (1,0) [48.0|67.2] "V" DEBUG

BO_ 121 BMS_ACCUMULATOR_SEGMENT_4: 4 BMS
SG_ SEGMENT_4_VOLTAGE : 0|32@1+ (1,0) [48.0|67.2] "V" DEBUG

BO_ 122 BMS_ACCUMULATOR_SEGMENT_5: 4 BMS
SG_ SEGMENT_5_VOLTAGE : 0|32@1+ (1,0) [48.0|67.2] "V" DEBUG

BO_ 123 BMS_CELL_MONITOR_0: 4 BMS
SG_ CELL_MONITOR_0_DIE_TEMPERATURE : 0|32@1+ (1,0) [0.0|120.0] "degC" DEBUG

BO_ 124 BMS_CELL_MONITOR_1: 4 BMS
SG_ CELL_MONITOR_1_DIE_TEMPERATURE : 0|32@1+ (1,0) [0.0|120.0] "degC" DEBUG

BO_ 125 BMS_CELL_MONITOR_2: 4 BMS
SG_ CELL_MONITOR_2_DIE_TEMPERATURE : 0|32@1+ (1,0) [0.0|120.0] "degC" DEBUG

BO_ 126 BMS_CELL_MONITOR_3: 4 BMS
SG_ CELL_MONITOR_3_DIE_TEMPERATURE : 0|32@1+ (1,0) [0.0|120.0] "degC" DEBUG

BO_ 127 BMS_CELL_MONITOR_4: 4 BMS
SG_ CELL_MONITOR_4_DIE_TEMPERATURE : 0|32@1+ (1,0) [0.0|120.0] "degC" DEBUG

BO_ 128 BMS_CELL_MONITOR_5: 4 BMS
SG_ CELL_MONITOR_5_DIE_TEMPERATURE : 0|32@1+ (1,0) [0.0|120.0] "degC" DEBUG

BO_ 129 BMS_MAX_CELL_MONITOR: 4 BMS
SG_ MAX_CELL_MONITOR_DIE_TEMPERATURE : 0|32@1+ (1,0) [0.0|120.0] "degC" DEBUG

BO_ 200 DCM_HEARTBEAT: 1 DCM
SG_ DUMMY_VARIABLE : 0|1@1+ (1,0) [0|1] "" BMS

BO_ 201 DCM_CAN_FIFO_OVERFLOW: 8 DCM
SG_ tx_overflow_count : 0|32@1+ (1,0) [0|4294967295] "" DEBUG
SG_ rx_overflow_count : 32|32@1+ (1,0) [0|4294967295] "" DEBUG

BO_ 202 DCM_STARTUP: 0 DCM

BO_ 203 DCM_WATCHDOG_TIMEOUT : 8 DCM
SG_ TASK_NAME : 0|64@1+ (1,0) [0|0] "" DEBUG

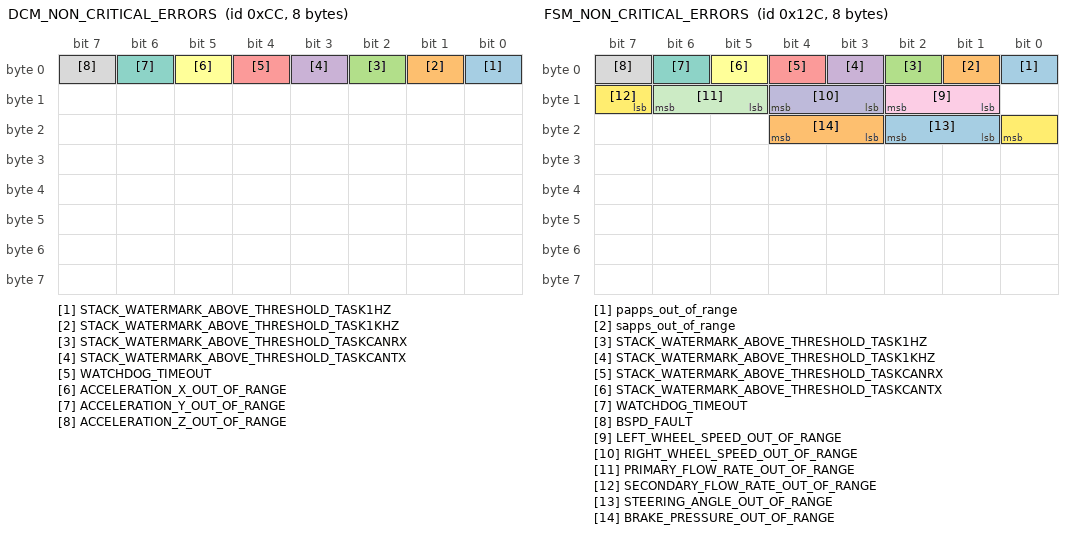
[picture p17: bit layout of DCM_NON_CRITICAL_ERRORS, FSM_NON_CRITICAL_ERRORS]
BO_ 204 DCM_NON_CRITICAL_ERRORS: 8 DCM
SG_ STACK_WATERMARK_ABOVE_THRESHOLD_TASK1HZ : 0|1@1+ (1,0) [0|1] "" DEBUG
SG_ STACK_WATERMARK_ABOVE_THRESHOLD_TASK1KHZ : 1|1@1+ (1,0) [0|1] "" DEBUG
SG_ STACK_WATERMARK_ABOVE_THRESHOLD_TASKCANRX : 2|1@1+ (1,0) [0|1] "" DEBUG
SG_ STACK_WATERMARK_ABOVE_THRESHOLD_TASKCANTX : 3|1@1+ (1,0) [0|1] "" DEBUG
SG_ WATCHDOG_TIMEOUT : 4|1@1+ (1,0) [0|1] "" DEBUG
SG_ ACCELERATION_X_OUT_OF_RANGE : 5|1@1+ (1,0) [0|1] "" DEBUG
SG_ ACCELERATION_Y_OUT_OF_RANGE : 6|1@1+ (1,0) [0|1] "" DEBUG
SG_ ACCELERATION_Z_OUT_OF_RANGE : 7|1@1+ (1,0) [0|1] "" DEBUG

BO_ 205 DCM_STATE_MACHINE : 1 DCM
SG_ State : 0|8@1+ (1,0) [0|255] "" DEBUG

BO_ 206 DCM_TORQUE_REQUEST : 4 DCM
SG_ Torque_Request : 0|32@1+ (1,0) [-3.4E038|3.4E038] "" LOGGER

BO_ 207 DCM_AIR_SHUTDOWN_ERRORS: 8 DCM
SG_ DUMMY_AIR_SHUTDOWN : 0|1@1+ (1,0) [0|1] "" DCM

BO_ 208 DCM_MOTOR_SHUTDOWN_ERRORS: 8 DCM
SG_ DUMMY_MOTOR_SHUTDOWN : 0|1@1+ (1,0) [0|1] "" DCM

BO_ 209 DCM_ACCELERATION_X: 4 DCM
SG_ ACCELERATION_X : 0|32@1+ (1,0) [-30.00|30.00] "m/s^2" DEBUG

BO_ 210 DCM_ACCELERATION_Y: 4 DCM
SG_ ACCELERATION_Y : 0|32@1+ (1,0) [-30.00|30.00] "m/s^2" DEBUG

BO_ 211 DCM_ACCELERATION_Z: 4 DCM
SG_ ACCELERATION_Z : 0|32@1+ (1,0) [-30.00|30.00] "m/s^2" DEBUG

BO_ 212 DCM_INVERTER_SWITCHES: 1 DCM
SG_ Right_Inverter_Switch : 0|1@1+ (1,0) [0|1] "" DEBUG
SG_ Left_Inverter_Switch : 1|1@1+ (1,0) [0|1] "" DEBUG

BO_ 300 FSM_NON_CRITICAL_ERRORS: 8 FSM
SG_ papps_out_of_range : 0|1@1+ (1,0) [0|1] "" DEBUG
SG_ sapps_out_of_range : 1|1@1+ (1,0) [0|1] "" DEBUG
SG_ STACK_WATERMARK_ABOVE_THRESHOLD_TASK1HZ : 2|1@1+ (1,0) [0|1] "" DEBUG
SG_ STACK_WATERMARK_ABOVE_THRESHOLD_TASK1KHZ : 3|1@1+ (1,0) [0|1] "" DEBUG
SG_ STACK_WATERMARK_ABOVE_THRESHOLD_TASKCANRX : 4|1@1+ (1,0) [0|1] "" DEBUG
SG_ STACK_WATERMARK_ABOVE_THRESHOLD_TASKCANTX : 5|1@1+ (1,0) [0|1] "" DEBUG
SG_ WATCHDOG_TIMEOUT : 6|1@1+ (1,0) [0|1] "" DEBUG
SG_ BSPD_FAULT : 7|1@1+ (1,0) [0|1] "" DIM
SG_ LEFT_WHEEL_SPEED_OUT_OF_RANGE: 9|2@1+ (1,0) [0|2] "" DEBUG
SG_ RIGHT_WHEEL_SPEED_OUT_OF_RANGE: 11|2@1+ (1,0) [0|2] ""  DEBUG
SG_ PRIMARY_FLOW_RATE_OUT_OF_RANGE: 13|2@1+ (1,0) [0|2] "" DEBUG
SG_ SECONDARY_FLOW_RATE_OUT_OF_RANGE: 15|2@1+ (1,0) [0|2] "" DEBUG
SG_ STEERING_ANGLE_OUT_OF_RANGE: 17|2@1+ (1,0) [0|2] "" DEBUG
SG_ BRAKE_PRESSURE_OUT_OF_RANGE: 19|2@1+ (1,0) [0|2] "" DEBUG

BO_ 301 FSM_HEARTBEAT: 1 FSM
SG_ DUMMY_VARIABLE : 0|1@1+ (1,0) [0|1] "" BMS

BO_ 302 FSM_CAN_FIFO_OVERFLOW: 8 FSM
SG_ tx_overflow_count : 0|32@1+ (1,0) [0|1] "" DEBUG
SG_ rx_overflow_count : 32|32@1+ (1,0) [0|1] "" DEBUG

BO_ 303 FSM_STARTUP: 0 FSM

BO_ 304 FSM_WATCHDOG_TIMEOUT : 8 FSM
SG_ TASK_NAME : 0|64@1+ (1,0) [0|0] "" DEBUG

BO_ 305 FSM_STATE_MACHINE : 1 FSM
SG_ State : 0|8@1+ (1,0) [0|255] "" DEBUG

BO_ 306 FSM_AIR_SHUTDOWN: 0 FSM

BO_ 307 FSM_FLOW_METER: 8 FSM
SG_ Primary_Flow_Rate : 0|32@1+ (1,0) [0|100] "L/min" DEBUG
SG_ Secondary_Flow_Rate : 32|32@1+ (1,0) [0|100] "L/min" DEBUG

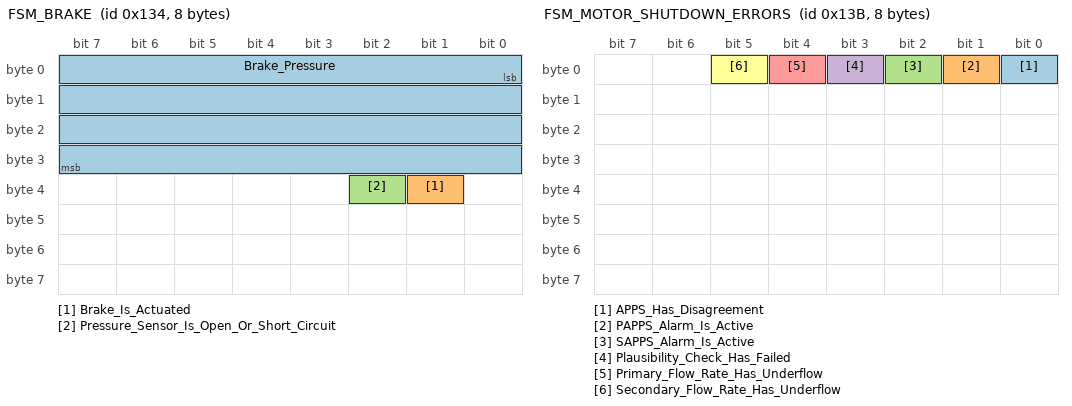
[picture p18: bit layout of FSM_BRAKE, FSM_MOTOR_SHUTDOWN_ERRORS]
BO_ 308 FSM_BRAKE: 8 FSM
SG_ Brake_Pressure: 0|32@1+ (1,0) [0|2500] "psi" DEBUG
SG_ Brake_Is_Actuated: 33|1@1+ (1,0) [0|1] "" DCM
SG_ Pressure_Sensor_Is_Open_Or_Short_Circuit: 34|1@1+ (1,0) [0|1] "" DEBUG

BO_ 310 FSM_AIR_SHUTDOWN_ERRORS: 8 FSM
SG_ DUMMY_AIR_SHUTDOWN : 0|1@1+ (1,0) [0|1] "" DCM

BO_ 313 FSM_PRIMARY_APPS: 4 FSM
SG_ Papps_Mapped_Pedal_Percentage : 0|32@1+ (1,0) [0|100] "%" DEBUG

BO_ 314 FSM_SECONDARY_APPS: 4 FSM
SG_ Sapps_Mapped_Pedal_Percentage : 0|32@1+ (1,0) [0|100] "%" DEBUG

BO_ 315 FSM_MOTOR_SHUTDOWN_ERRORS: 8 FSM
SG_ APPS_Has_Disagreement : 0|1@1+ (1,0) [0|1] "" DCM
SG_ PAPPS_Alarm_Is_Active : 1|1@1+ (1,0) [0|1] "" DCM
SG_ SAPPS_Alarm_Is_Active : 2|1@1+ (1,0) [0|1] "" DCM
SG_ Plausibility_Check_Has_Failed : 3|1@1+ (1,0) [0|1] "" DCM
SG_ Primary_Flow_Rate_Has_Underflow : 4|1@1+ (1,0) [0|1] "" DCM
SG_ Secondary_Flow_Rate_Has_Underflow : 5|1@1+ (1,0) [0|1] "" DCM

BO_ 316 FSM_PEDAL_POSITION: 4 FSM
SG_ Mapped_Pedal_Percentage: 0|32@1+ (1,0) [0|100] "%" DCM

BO_ 317 FSM_WHEEL_SPEED_SENSOR: 8 FSM
SG_ Left_Wheel_Speed : 0|32@1+ (1,0) [0|150] "km/h" DCM
SG_ Right_Wheel_Speed : 32|32@1+ (1,0) [0|150] "km/h" DCM

BO_ 318 FSM_STEERING_ANGLE_SENSOR: 4 FSM
SG_ Steering_Angle : 0|32@1+ (1,0) [-110|110] "deg" DCM

BO_ 400 PDM_NON_CRITICAL_ERRORS: 8 PDM
SG_ MISSING_HEARTBEAT : 0|1@1+ (1,0) [0|1] "" DEBUG
SG_ BOOST_PGOOD_FAULT : 1|1@1+ (1,0) [0|1] "" DEBUG
SG_ CHARGER_FAULT : 3|1@1+ (1,0) [0|1] "" DEBUG
SG_ EFUSE_FAULT : 4|1@1+ (1,0) [0|1] "" DEBUG
SG_ STACK_WATERMARK_ABOVE_THRESHOLD_TASK1HZ : 5|1@1+ (1,0) [0|1] "" DEBUG
SG_ STACK_WATERMARK_ABOVE_THRESHOLD_TASK1KHZ : 6|1@1+ (1,0) [0|1] "" DEBUG
SG_ STACK_WATERMARK_ABOVE_THRESHOLD_TASKCANRX : 7|1@1+ (1,0) [0|1] "" DEBUG
SG_ STACK_WATERMARK_ABOVE_THRESHOLD_TASKCANTX : 8|1@1+ (1,0) [0|1] "" DEBUG
SG_ WATCHDOG_TIMEOUT : 9|1@1+ (1,0) [0|1] "" DEBUG
SG_ VBAT_VOLTAGE_OUT_OF_RANGE : 10|2@1+ (1,0) [0|2] "" DEBUG
SG_ _24V_AUX_VOLTAGE_OUT_OF_RANGE : 12|2@1+ (1,0) [0|2] "" DEBUG
SG_ _24V_ACC_VOLTAGE_OUT_OF_RANGE : 14|2@1+ (1,0) [0|2] "" DEBUG
SG_ AUX1_CURRENT_OUT_OF_RANGE : 16|2@1+ (1,0) [0|2] "" DEBUG
SG_ AUX2_CURRENT_OUT_OF_RANGE : 18|2@1+ (1,0) [0|2] "" DEBUG
SG_ LEFT_INVERTER_CURRENT_OUT_OF_RANGE : 20|2@1+ (1,0) [0|2] "" DEBUG
SG_ RIGHT_INVERTER_CURRENT_OUT_OF_RANGE : 22|2@1+ (1,0) [0|2] "" DEBUG
SG_ ENERGY_METER_CURRENT_OUT_OF_RANGE : 24|2@1+ (1,0) [0|2] "" DEBUG
SG_ CAN_CURRENT_OUT_OF_RANGE : 26|2@1+ (1,0) [0|2] "" DEBUG
SG_ AIR_SHUTDOWN_CURRENT_OUT_OF_RANGE : 28|2@1+ (1,0) [0|2] "" DEBUG

BO_ 401 PDM_HEARTBEAT: 1 PDM
SG_ DUMMY_VARIABLE : 0|1@1+ (1,0) [0|1] "" BMS

BO_ 402 PDM_CAN_FIFO_OVERFLOW: 8 PDM
SG_ tx_overflow_count : 0|32@1+ (1,0) [0|4294967295] "" DEBUG
SG_ rx_overflow_count : 32|32@1+ (1,0) [0|4294967295] "" DEBUG

BO_ 403 PDM_STARTUP: 0 PDM

BO_ 405 PDM_MOTOR_SHUTDOWN_ERRORS: 8 PDM
SG_ DUMMY_MOTOR_SHUTDOWN : 0|1@1+ (1,0) [0|1] "" DCM

BO_ 406 PDM_AUX1_AUX2_CURRENT: 8 PDM
SG_ Auxiliary1_Current : 0|32@1- (1,0) [0|1E2] "A" DEBUG
SG_ Auxiliary2_Current : 32|32@1- (1,0) [0|1E2] "A" DEBUG

BO_ 407 PDM_ENERGY_METER_CURRENT: 8 PDM
SG_ Energy_Meter_Current : 0|32@1- (1,0) [0|1E2] "A" DEBUG
SG_ Unused : 32|32@1- (1,0) [0|1E2] "A" DEBUG

BO_ 408 PDM_AIRSHDN_CANGLV_CURRENT: 8 PDM
SG_ CAN_Current : 0|32@1- (1,0) [0|1E2] "A" DEBUG
SG_ AIR_Shutdown_Current : 32|32@1- (1,0) [0|1E2] "A" DEBUG

BO_ 409 PDM_INVERTER_CURRENT: 8 PDM
SG_ Left_Inverter_Current : 0|32@1- (1,0) [0|1E2] "A" DEBUG
SG_ Right_Inverter_Current : 32|32@1- (1,0) [0|1E2] "A" DEBUG

BO_ 410 PDM_24V: 8 PDM
SG_ _24V_AUX : 0|32@1- (1,0) [0|1E2] "V" DEBUG
SG_ _24V_ACC: 32|32@1- (1,0) [0|1E2] "V" DEBUG

BO_ 411 PDM_VBAT: 4 PDM
SG_ VBAT : 0|32@1- (1,0) [0|1E2] "V" DEBUG

BO_ 412 PDM_WATCHDOG_TIMEOUT: 8 PDM
SG_ TASK_NAME : 0|64@1+ (1,0) [0|0] "" DEBUG

BO_ 413 PDM_STATE_MACHINE : 1 PDM
SG_ State : 0|8@1+ (1,0) [0|255] "" DEBUG

BO_ 414 PDM_AIR_SHUTDOWN_ERRORS: 8 PDM
SG_ DUMMY_AIR_SHUTDOWN : 0|1@1+ (1,0) [0|1] "" DCM

BO_ 500 DIM_HEARTBEAT: 1 DIM
SG_ DUMMY_VARIABLE : 0|1@1+ (1,0) [0|1] "" FSM,DCM,PDM,BMS

BO_ 501 DIM_CAN_FIFO_OVERFLOW: 8 DIM
SG_ tx_overflow_count : 0|32@1+ (1,0) [0|4294967295] "" DEBUG
SG_ rx_overflow_count : 32|32@1+ (1,0) [0|4294967295] "" DEBUG

BO_ 502 DIM_STARTUP: 0 DIM

BO_ 503 DIM_STATE_MACHINE : 1 DIM
SG_ State : 0|8@1+ (1,0) [0|255] "" DEBUG

BO_ 504 DIM_WATCHDOG_TIMEOUT: 8 DIM
SG_ TASK_NAME : 0|64@1+ (1,0) [0|0] "" DEBUG

BO_ 505 DIM_REGEN_PADDLE: 8 DIM
SG_ Raw_Paddle_Position : 0|32@1+ (1,0) [0|100] "%" DEBUG
SG_ Mapped_Paddle_Position : 32|32@1+ (1,0) [0|100] "%" DCM

BO_ 506 DIM_DRIVE_MODE_SWITCH: 1 DIM
SG_ Drive_Mode : 0|3@1+ (1,0) [0|5] "" DCM

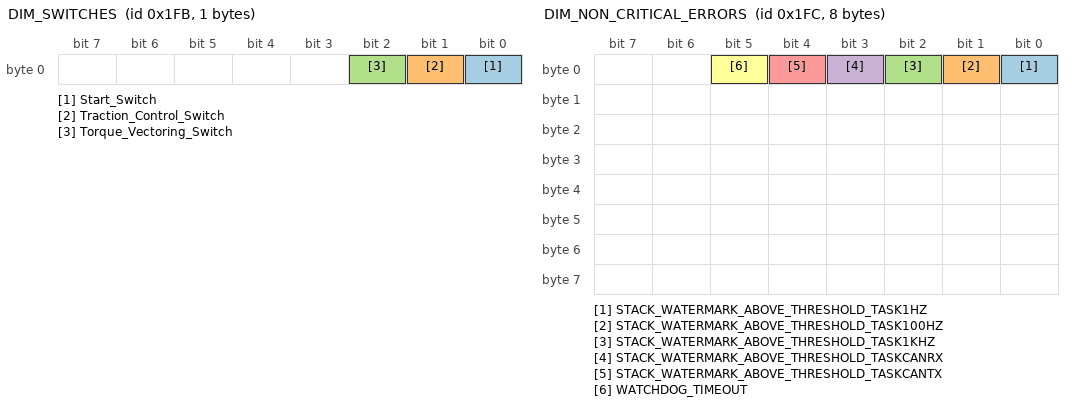
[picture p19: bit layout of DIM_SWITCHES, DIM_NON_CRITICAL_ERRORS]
BO_ 507 DIM_SWITCHES: 1 DIM
SG_ Start_Switch : 0|1@1+ (1,0) [0|1] "" DCM
SG_ Traction_Control_Switch : 1|1@1+ (1,0) [0|1] "" DCM
SG_ Torque_Vectoring_Switch : 2|1@1+ (1,0) [0|1] "" DCM

BO_ 508 DIM_NON_CRITICAL_ERRORS: 8 DIM
SG_ STACK_WATERMARK_ABOVE_THRESHOLD_TASK1HZ : 0|1@1+ (1,0) [0|1] "" LOGGER
SG_ STACK_WATERMARK_ABOVE_THRESHOLD_TASK100HZ : 1|1@1+ (1,0) [0|1] "" LOGGER
SG_ STACK_WATERMARK_ABOVE_THRESHOLD_TASK1KHZ : 2|1@1+ (1,0) [0|1] "" LOGGER
SG_ STACK_WATERMARK_ABOVE_THRESHOLD_TASKCANRX : 3|1@1+ (1,0) [0|1] "" LOGGER
SG_ STACK_WATERMARK_ABOVE_THRESHOLD_TASKCANTX : 4|1@1+ (1,0) [0|1] "" LOGGER
SG_ WATCHDOG_TIMEOUT : 5|1@1+ (1,0) [0|1] "" LOGGER

BO_ 509 DIM_AIR_SHUTDOWN_ERRORS: 8 DIM
SG_ DUMMY_AIR_SHUTDOWN : 0|1@1+ (1,0) [0|1] "" DCM

BO_ 510 DIM_MOTOR_SHUTDOWN_ERRORS: 8 DIM
SG_ DUMMY_MOTOR_SHUTDOWN : 0|1@1+ (1,0) [0|1] "" DCM

BA_DEF_  "BusType" STRING ;
BA_DEF_ BO_  "GenMsgCycleTime" INT 0 65535;
BA_DEF_ SG_  "GenSigStartValue" INT 0 2147483647;

BA_DEF_DEF_  "BusType" "CAN";
BA_DEF_DEF_  "GenMsgCycleTime" 0;
BA_DEF_DEF_  "GenSigStartValue" 0;

BA_ "GenSigStartValue" SG_ 507 Start_Switch 1;

BA_ "GenMsgCycleTime" BO_ 0 100;
BA_ "GenMsgCycleTime" BO_ 1 100;
BA_ "GenMsgCycleTime" BO_ 2 100;
BA_ "GenMsgCycleTime" BO_ 3 10;
BA_ "GenMsgCycleTime" BO_ 4 10;
BA_ "GenMsgCycleTime" BO_ 5 10;
BA_ "GenMsgCycleTime" BO_ 6 10;
BA_ "GenMsgCycleTime" BO_ 7 10;
BA_ "GenMsgCycleTime" BO_ 8 10;
BA_ "GenMsgCycleTime" BO_ 9 100;
BA_ "GenMsgCycleTime" BO_ 10 100;
BA_ "GenMsgCycleTime" BO_ 11 100;
BA_ "GenMsgCycleTime" BO_ 12 10;
BA_ "GenMsgCycleTime" BO_ 16 3;
BA_ "GenMsgCycleTime" BO_ 32 10;

BA_ "GenMsgCycleTime" BO_ 50 100;
BA_ "GenMsgCycleTime" BO_ 51 100;
BA_ "GenMsgCycleTime" BO_ 52 100;
BA_ "GenMsgCycleTime" BO_ 53 10;
BA_ "GenMsgCycleTime" BO_ 54 10;
BA_ "GenMsgCycleTime" BO_ 55 10;
BA_ "GenMsgCycleTime" BO_ 56 10;
BA_ "GenMsgCycleTime" BO_ 57 10;
BA_ "GenMsgCycleTime" BO_ 58 10;
BA_ "GenMsgCycleTime" BO_ 59 100;
BA_ "GenMsgCycleTime" BO_ 60 100;
BA_ "GenMsgCycleTime" BO_ 61 100;
BA_ "GenMsgCycleTime" BO_ 62 10;
BA_ "GenMsgCycleTime" BO_ 66 3;
BA_ "GenMsgCycleTime" BO_ 82 10;

BA_ "GenMsgCycleTime" BO_ 100 100;
BA_ "GenMsgCycleTime" BO_ 101 5000;
BA_ "GenMsgCycleTime" BO_ 104 1000;
BA_ "GenMsgCycleTime" BO_ 105 1000;
BA_ "GenMsgCycleTime" BO_ 106 1000;
BA_ "GenMsgCycleTime" BO_ 107 10;
BA_ "GenMsgCycleTime" BO_ 108 10;
BA_ "GenMsgCycleTime" BO_ 109 1000;
BA_ "GenMsgCycleTime" BO_ 110 1000;
BA_ "GenMsgCycleTime" BO_ 111 10;
BA_ "GenMsgCycleTime" BO_ 112 10;
BA_ "GenMsgCycleTime" BO_ 113 1000;
BA_ "GenMsgCycleTime" BO_ 114 10;
BA_ "GenMsgCycleTime" BO_ 115 10;
BA_ "GenMsgCycleTime" BO_ 116 10;
BA_ "GenMsgCycleTime" BO_ 117 10;
BA_ "GenMsgCycleTime" BO_ 118 10;
BA_ "GenMsgCycleTime" BO_ 119 10;
BA_ "GenMsgCycleTime" BO_ 120 10;
BA_ "GenMsgCycleTime" BO_ 121 10;
BA_ "GenMsgCycleTime" BO_ 122 10;
BA_ "GenMsgCycleTime" BO_ 123 1000;
BA_ "GenMsgCycleTime" BO_ 124 1000;
BA_ "GenMsgCycleTime" BO_ 125 1000;
BA_ "GenMsgCycleTime" BO_ 126 1000;
BA_ "GenMsgCycleTime" BO_ 127 1000;
BA_ "GenMsgCycleTime" BO_ 128 1000;
BA_ "GenMsgCycleTime" BO_ 129 1000;

BA_ "GenMsgCycleTime" BO_ 200 100;
BA_ "GenMsgCycleTime" BO_ 201 5000;
BA_ "GenMsgCycleTime" BO_ 204 1000;
BA_ "GenMsgCycleTime" BO_ 205 10;
BA_ "GenMsgCycleTime" BO_ 206 10;
BA_ "GenMsgCycleTime" BO_ 207 1000;
BA_ "GenMsgCycleTime" BO_ 208 1000;
BA_ "GenMsgCycleTime" BO_ 209 10;
BA_ "GenMsgCycleTime" BO_ 210 10;
BA_ "GenMsgCycleTime" BO_ 211 10;
BA_ "GenMsgCycleTime" BO_ 212 10;
BA_ "GenMsgCycleTime" BO_ 510 100;
BA_ "GenMsgCycleTime" BO_ 300 1000;
BA_ "GenMsgCycleTime" BO_ 301 100;
BA_ "GenMsgCycleTime" BO_ 302 5000;
BA_ "GenMsgCycleTime" BO_ 305 10;
BA_ "GenMsgCycleTime" BO_ 307 1000;
BA_ "GenMsgCycleTime" BO_ 308 10;
BA_ "GenMsgCycleTime" BO_ 310 1000;
BA_ "GenMsgCycleTime" BO_ 313 10;
BA_ "GenMsgCycleTime" BO_ 314 10;
BA_ "GenMsgCycleTime" BO_ 315 1000;
BA_ "GenMsgCycleTime" BO_ 316 100;
BA_ "GenMsgCycleTime" BO_ 317 10;
BA_ "GenMsgCycleTime" BO_ 318 10;
BA_ "GenMsgCycleTime" BO_ 400 1000;
BA_ "GenMsgCycleTime" BO_ 401 100;
BA_ "GenMsgCycleTime" BO_ 402 5000;
BA_ "GenMsgCycleTime" BO_ 405 1000;
BA_ "GenMsgCycleTime" BO_ 406 1000;
BA_ "GenMsgCycleTime" BO_ 407 1000;
BA_ "GenMsgCycleTime" BO_ 408 1000;
BA_ "GenMsgCycleTime" BO_ 409 1000;
BA_ "GenMsgCycleTime" BO_ 410 1000;
BA_ "GenMsgCycleTime" BO_ 411 1000;
BA_ "GenMsgCycleTime" BO_ 413 10;
BA_ "GenMsgCycleTime" BO_ 414 1000;
BA_ "GenMsgCycleTime" BO_ 500 100;
BA_ "GenMsgCycleTime" BO_ 501 5000;
BA_ "GenMsgCycleTime" BO_ 503 10;
BA_ "GenMsgCycleTime" BO_ 505 10;
BA_ "GenMsgCycleTime" BO_ 506 10;
BA_ "GenMsgCycleTime" BO_ 507 10;
BA_ "GenMsgCycleTime" BO_ 508 1000;
BA_ "GenMsgCycleTime" BO_ 509 1000;
BA_ "GenMsgCycleTime" BO_ 510 1000;

SIG_VALTYPE_ 106 Duty_Cycle : 1;
SIG_VALTYPE_ 106 Frequency : 1;
SIG_VALTYPE_ 108 State_Of_Charge : 1;
SIG_VALTYPE_ 114 MIN_CELL_VOLTAGE : 1;
SIG_VALTYPE_ 114 MAX_CELL_VOLTAGE : 1;
SIG_VALTYPE_ 115 PACK_VOLTAGE : 1;
SIG_VALTYPE_ 116 AVERAGE_CELL_VOLTAGE : 1;
SIG_VALTYPE_ 117 SEGMENT_0_VOLTAGE : 1;
SIG_VALTYPE_ 118 SEGMENT_1_VOLTAGE : 1;
SIG_VALTYPE_ 119 SEGMENT_2_VOLTAGE : 1;
SIG_VALTYPE_ 120 SEGMENT_3_VOLTAGE : 1;
SIG_VALTYPE_ 121 SEGMENT_4_VOLTAGE : 1;
SIG_VALTYPE_ 122 SEGMENT_5_VOLTAGE : 1;
SIG_VALTYPE_ 123 CELL_MONITOR_0_DIE_TEMPERATURE : 1;
SIG_VALTYPE_ 124 CELL_MONITOR_1_DIE_TEMPERATURE : 1;
SIG_VALTYPE_ 125 CELL_MONITOR_2_DIE_TEMPERATURE : 1;
SIG_VALTYPE_ 126 CELL_MONITOR_3_DIE_TEMPERATURE : 1;
SIG_VALTYPE_ 127 CELL_MONITOR_4_DIE_TEMPERATURE : 1;
SIG_VALTYPE_ 128 CELL_MONITOR_5_DIE_TEMPERATURE : 1;
SIG_VALTYPE_ 129 MAX_CELL_MONITOR_DIE_TEMPERATURE : 1;
SIG_VALTYPE_ 206 Torque_Request : 1;
SIG_VALTYPE_ 209 ACCELERATION_X : 1;
SIG_VALTYPE_ 210 ACCELERATION_Y : 1;
SIG_VALTYPE_ 211 ACCELERATION_Z : 1;
SIG_VALTYPE_ 307 Primary_Flow_Rate: 1;
SIG_VALTYPE_ 307 Secondary_Flow_Rate: 1;
SIG_VALTYPE_ 308 Brake_Pressure: 1;
SIG_VALTYPE_ 313 Papps_Mapped_Pedal_Percentage : 1;
SIG_VALTYPE_ 314 Sapps_Mapped_Pedal_Percentage : 1;
SIG_VALTYPE_ 316 Mapped_Pedal_Percentage : 1;
SIG_VALTYPE_ 317 Left_Wheel_Speed: 1;
SIG_VALTYPE_ 317 Right_Wheel_Speed: 1;
SIG_VALTYPE_ 318 Steering_Angle: 1;
SIG_VALTYPE_ 406 Auxiliary1_Current : 1;
SIG_VALTYPE_ 406 Auxiliary2_Current : 1;
SIG_VALTYPE_ 407 Energy_Meter_Current : 1;
SIG_VALTYPE_ 408 AIR_Shutdown_Current : 1;
SIG_VALTYPE_ 408 CAN_Current : 1;
SIG_VALTYPE_ 409 Left_Inverter_Current : 1;
SIG_VALTYPE_ 409 Right_Inverter_Current : 1;
SIG_VALTYPE_ 410 _24V_AUX : 1;
SIG_VALTYPE_ 410 _24V_ACC : 1;
SIG_VALTYPE_ 411 VBAT : 1;

VAL_ 10 D2_Inverter_State_INVR 0 "Power up" 1 "Stop" 2 "Open Loop" 3 "Closed Loop" 4 "Internal State" 5 "Internal State" 6 "Internal State" 7 "Internal State" 8 "Idle Run" 9 "Idle Stop" 10 "Internal State" 11 "Intern State" 12 "Internal State";
VAL_ 10 D1_VSM_State_INVR 0 "VSM Start State" 1 "Pre-Charge Init state" 2 "pre-charge active state" 3 "pre-charge complete state" 4 "VSM wait state" 5 "VSM ready state" 6 "Motor Running State" 7 "blink fault code state" 14 "Shutdown state for Key Switch Mode 1" 15 "Reset the inverter";
VAL_ 32 Inverter_Enable_INVR 0 "OFF" 1 "ON";
VAL_ 32 Direction_Command_INVR 0 "CW" 1 "CCW";
VAL_ 32 Inverter_Discharge_INVR 0 "Discharge Disable" 1 "Discharge Enable (if EEPROM parameter is set)";

VAL_ 60 D2_Inverter_State_INVL 0 "Power up" 1 "Stop" 2 "Open Loop" 3 "Closed Loop" 4 "Internal State" 5 "Internal State" 6 "Internal State" 7 "Internal State" 8 "Idle Run" 9 "Idle Stop" 10 "Internal State" 11 "Intern State" 12 "Internal State";
VAL_ 60 D1_VSM_State_INVL 0 "VSM Start State" 1 "Pre-Charge Init state" 2 "pre-charge active state" 3 "pre-charge complete state" 4 "VSM wait state" 5 "VSM ready state" 6 "Motor Running State" 7 "blink fault code state" 14 "Shutdown state for Key Switch Mode 1" 15 "Reset the inverter";
VAL_ 82 Inverter_Enable_INVL 0 "OFF" 1 "ON";
VAL_ 82 Direction_Command_INVL 0 "CW" 1 "CCW";
VAL_ 82 Inverter_Discharge_INVL 0 "Discharge Disable" 1 "Discharge Enable (if EEPROM parameter is set)";

VAL_ 104 SEGMENT_0_VOLTAGE_OUT_OF_RANGE 0 "OK" 1 "UNDERFLOW" 2 "OVERFLOW";
VAL_ 104 SEGMENT_1_VOLTAGE_OUT_OF_RANGE 0 "OK" 1 "UNDERFLOW" 2 "OVERFLOW";
VAL_ 104 SEGMENT_2_VOLTAGE_OUT_OF_RANGE 0 "OK" 1 "UNDERFLOW" 2 "OVERFLOW";
VAL_ 104 SEGMENT_3_VOLTAGE_OUT_OF_RANGE 0 "OK" 1 "UNDERFLOW" 2 "OVERFLOW";
VAL_ 104 SEGMENT_4_VOLTAGE_OUT_OF_RANGE 0 "OK" 1 "UNDERFLOW" 2 "OVERFLOW";
VAL_ 104 SEGMENT_5_VOLTAGE_OUT_OF_RANGE 0 "OK" 1 "UNDERFLOW" 2 "OVERFLOW";
VAL_ 104 PACK_VOLTAGE_OUT_OF_RANGE 0 "OK" 1 "UNDERFLOW" 2 "OVERFLOW";
VAL_ 104 AVERAGE_CELL_VOLTAGE_OUT_OF_RANGE 0 "OK" 1 "UNDERFLOW" 2 "OVERFLOW";
VAL_ 104 CELL_MONITOR_0_DIE_TEMP_OUT_OF_RANGE 0 "OK" 1 "UNDERFLOW" 2 "OVERFLOW";
VAL_ 104 CELL_MONITOR_1_DIE_TEMP_OUT_OF_RANGE 0 "OK" 1 "UNDERFLOW" 2 "OVERFLOW";
VAL_ 104 CELL_MONITOR_2_DIE_TEMP_OUT_OF_RANGE 0 "OK" 1 "UNDERFLOW" 2 "OVERFLOW";
VAL_ 104 CELL_MONITOR_3_DIE_TEMP_OUT_OF_RANGE 0 "OK" 1 "UNDERFLOW" 2 "OVERFLOW";
VAL_ 104 CELL_MONITOR_4_DIE_TEMP_OUT_OF_RANGE 0 "OK" 1 "UNDERFLOW" 2 "OVERFLOW";
VAL_ 104 CELL_MONITOR_5_DIE_TEMP_OUT_OF_RANGE 0 "OK" 1 "UNDERFLOW" 2 "OVERFLOW";
VAL_ 104 ITMP_CHARGER_HAS_OVERFLOW 0 "FALSE" 1 "TRUE";
VAL_ 105 Condition 0 "IMD_SHORT_CIRCUIT" 1 "IMD_NORMAL" 2 "IMD_UNDERVOLTAGE_DETECTED" 3 "IMD_SST" 4 "IMD_DEVICE_ERROR" 5 "IMD_EARTH_FAULT" 6 "IMD_INVALID";
VAL_ 105 OK_HS 0 "NO FAULT" 1 "FAULT";
VAL_ 107 State 0 "INIT" 1 "AIR_OPEN" 2 "PRE_CHARGE" 3 "CHARGE" 4 "DRIVE" 5 "FAULT";
VAL_ 109 CHARGER_DISCONNECTED_IN_CHARGE_STATE  0 "FALSE" 1 "TRUE";
VAL_ 109 MIN_CELL_VOLTAGE_OUT_OF_RANGE 0 "OK" 1 "UNDERFLOW" 2 "OVERFLOW";
VAL_ 109 MAX_CELL_VOLTAGE_OUT_OF_RANGE 0 "OK" 1 "UNDERFLOW" 2 "OVERFLOW";
VAL_ 112 AIR_POSITIVE 0 "OPEN" 1 "CLOSED";
VAL_ 112 AIR_NEGATIVE 0 "OPEN" 1 "CLOSED";

VAL_ 123 SEGMENT_0_VOLTAGE_OUT_OF_RANGE 0 "OK" 1 "UNDERFLOW" 2 "OVERFLOW";
VAL_ 123 SEGMENT_1_VOLTAGE_OUT_OF_RANGE 0 "OK" 1 "UNDERFLOW" 2 "OVERFLOW";
VAL_ 123 SEGMENT_2_VOLTAGE_OUT_OF_RANGE 0 "OK" 1 "UNDERFLOW" 2 "OVERFLOW";
VAL_ 123 SEGMENT_3_VOLTAGE_OUT_OF_RANGE 0 "OK" 1 "UNDERFLOW" 2 "OVERFLOW";
VAL_ 123 SEGMENT_4_VOLTAGE_OUT_OF_RANGE 0 "OK" 1 "UNDERFLOW" 2 "OVERFLOW";
VAL_ 123 SEGMENT_5_VOLTAGE_OUT_OF_RANGE 0 "OK" 1 "UNDERFLOW" 2 "OVERFLOW";
VAL_ 123 PACK_VOLTAGE_OUT_OF_RANGE 0 "OK" 1 "UNDERFLOW" 2 "OVERFLOW";
VAL_ 123 AVERAGE_CELL_VOLTAGE_OUT_OF_RANGE 0 "OK" 1 "UNDERFLOW" 2 "OVERFLOW";

VAL_ 204 ACCELERATION_X_OUT_OF_RANGE 0 "OK" 1 "UNDERFLOW" 2 "OVERFLOW";
VAL_ 204 ACCELERATION_Y_OUT_OF_RANGE 0 "OK" 1 "UNDERFLOW" 2 "OVERFLOW";
VAL_ 204 ACCELERATION_Z_OUT_OF_RANGE 0 "OK" 1 "UNDERFLOW" 2 "OVERFLOW";

VAL_ 205 State 0 "INIT" 1 "DRIVE" 2 "FAULT";
VAL_ 212 Right_Inverter_Switch 0 "OFF" 1 "ON";
VAL_ 212 Left_Inverter_Switch 0 "OFF" 1 "ON";
VAL_ 300 LEFT_WHEEL_SPEED_OUT_OF_RANGE 0 "OK" 1 "UNDERFLOW" 2 "OVERFLOW";
VAL_ 300 RIGHT_WHEEL_SPEED_OUT_OF_RANGE 0 "OK" 1 "UNDERFLOW" 2 "OVERFLOW";
VAL_ 300 PRIMARY_FLOW_RATE_OUT_OF_RANGE 0 "OK" 1 "UNDERFLOW" 2 "OVERFLOW";
VAL_ 300 SECONDARY_FLOW_RATE_OUT_OF_RANGE 0 "OK" 1 "UNDERFLOW" 2 "OVERFLOW";
VAL_ 300 STEERING_ANGLE_OUT_OF_RANGE 0 "OK" 1 "UNDERFLOW" 2 "OVERFLOW";
VAL_ 300 BRAKE_PRESSURE_OUT_OF_RANGE 0 "OK" 1 "UNDERFLOW" 2 "OVERFLOW";
VAL_ 305 State 0 "AIR_OPEN" 1 "AIR_CLOSED";
VAL_ 308 Brake_Is_Actuated 0 "FALSE" 1 "TRUE";
VAL_ 308 Pressure_Sensor_Is_Open_Or_Short_Circuit 0 "FALSE" 1 "TRUE";
VAL_ 315 APPS_Has_Disagreement 0 "FALSE" 1 "TRUE";
VAL_ 315 PAPPS_Alarm_Is_Active 0 "FALSE" 1 "TRUE";
VAL_ 315 SAPPS_Alarm_Is_Active 0 "FALSE" 1 "TRUE";
VAL_ 315 Plausibility_Check_Has_Failed 0 "FALSE" 1 "TRUE";
VAL_ 315 Primary_Flow_Rate_Has_Underflow 0 "FALSE" 1 "TRUE";
VAL_ 315 Secondary_Flow_Rate_Has_Underflow 0 "FALSE" 1 "TRUE";
VAL_ 400 VBAT_VOLTAGE_OUT_OF_RANGE 0 "OK" 1 "UNDERFLOW" 2 "OVERFLOW";
VAL_ 400 _24V_AUX_VOLTAGE_OUT_OF_RANGE 0 "OK" 1 "UNDERFLOW" 2 "OVERFLOW";
VAL_ 400 _24V_ACC_VOLTAGE_OUT_OF_RANGE 0 "OK" 1 "UNDERFLOW" 2 "OVERFLOW";
VAL_ 400 AUX1_CURRENT_OUT_OF_RANGE 0 "OK" 1 "UNDERFLOW" 2 "OVERFLOW";
VAL_ 400 AUX2_CURRENT_OUT_OF_RANGE 0 "OK" 1 "UNDERFLOW" 2 "OVERFLOW";
VAL_ 400 LEFT_INVERTER_CURRENT_OUT_OF_RANGE 0 "OK" 1 "UNDERFLOW" 2 "OVERFLOW";
VAL_ 400 RIGHT_INVERTER_CURRENT_OUT_OF_RANGE 0 "OK" 1 "UNDERFLOW" 2 "OVERFLOW";
VAL_ 400 ENERGY_METER_CURRENT_OUT_OF_RANGE 0 "OK" 1 "UNDERFLOW" 2 "OVERFLOW";
VAL_ 400 CAN_CURRENT_OUT_OF_RANGE 0 "OK" 1 "UNDERFLOW" 2 "OVERFLOW";
VAL_ 400 AIR_SHUTDOWN_CURRENT_OUT_OF_RANGE 0 "OK" 1 "UNDERFLOW" 2 "OVERFLOW";
VAL_ 413 State 0 "INIT" 1 "AIR_OPEN" 2 "AIR_CLOSED";
VAL_ 503 State 0 "DRIVE";
VAL_ 506 Drive_Mode 0 "DRIVE_MODE_1" 1 "DRIVE_MODE_2" 2 "DRIVE_MODE_3" 3 "DRIVE_MODE_4" 4 "DRIVE_MODE_5" 5 "DRIVE_MODE_INVALID";
VAL_ 507 Start_Switch 0 "OFF" 1 "ON";
VAL_ 507 Traction_Control_Switch 0 "OFF" 1 "ON";
VAL_ 507 Torque_Vectoring_Switch  0 "OFF" 1 "ON";
